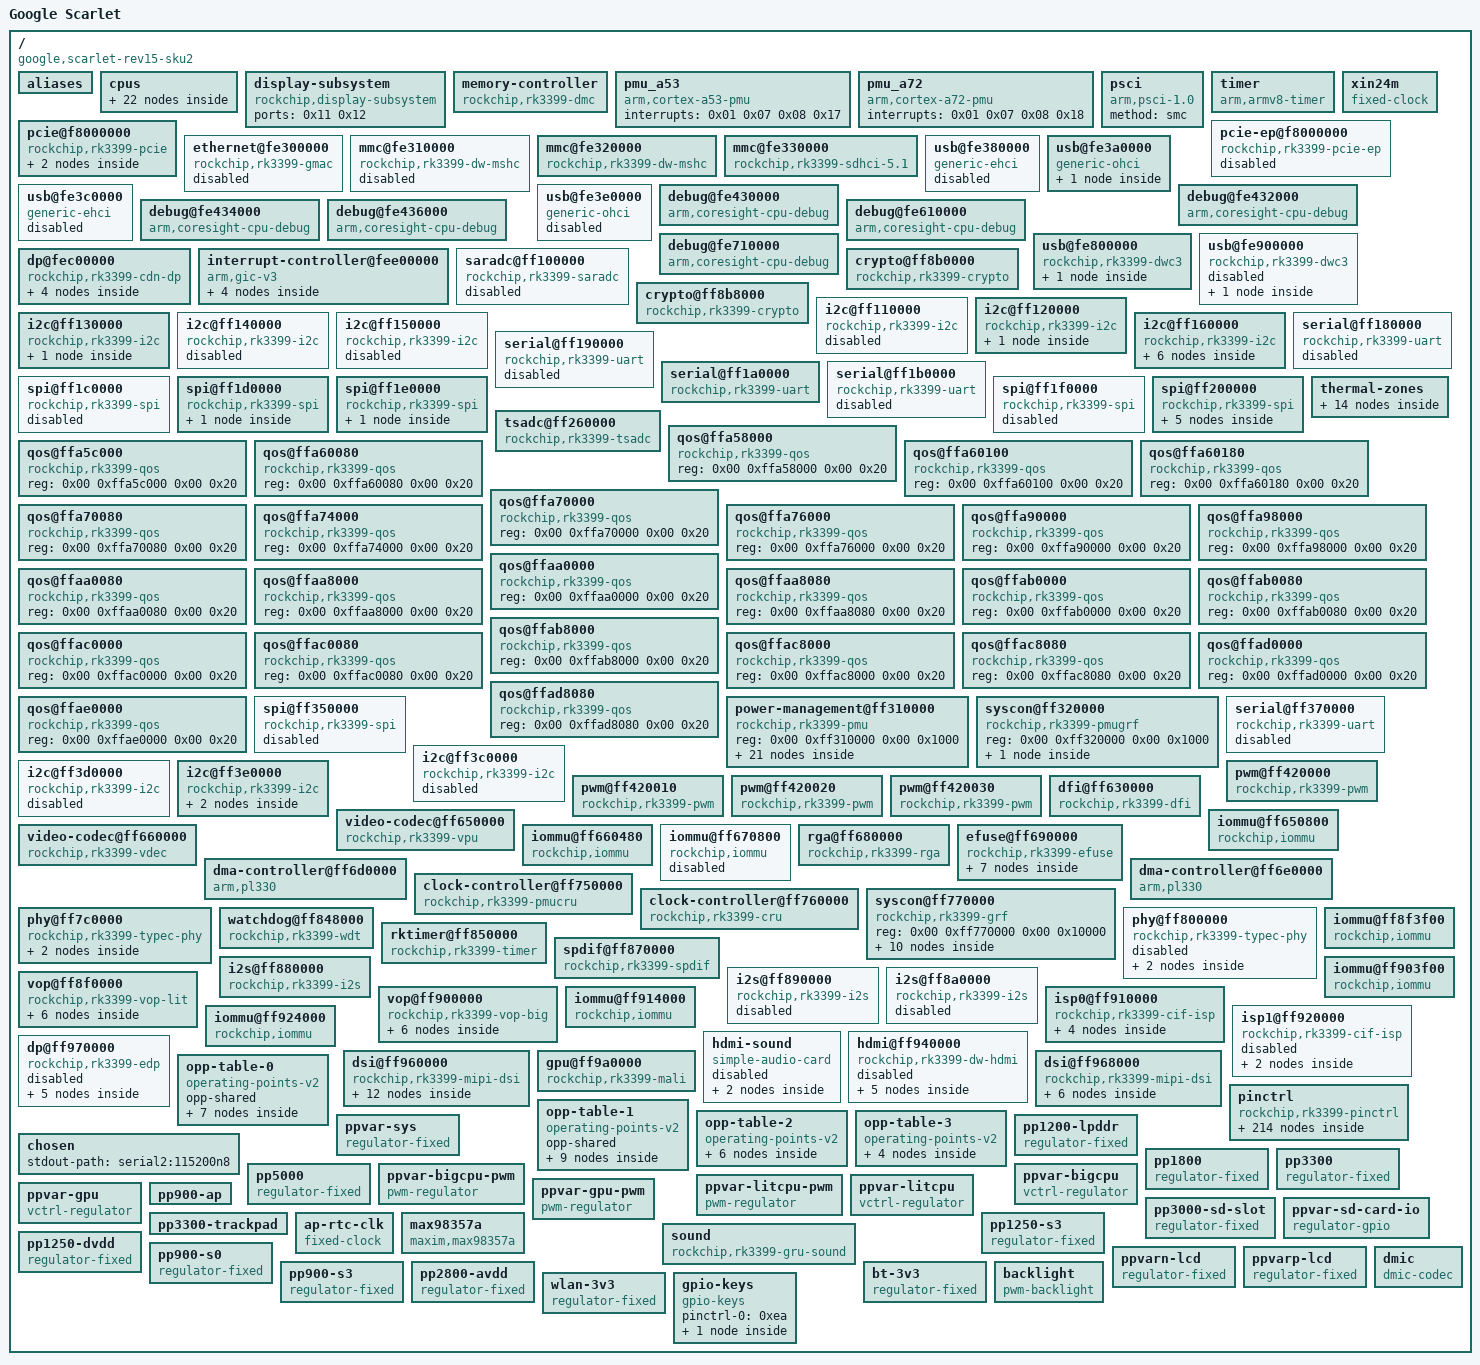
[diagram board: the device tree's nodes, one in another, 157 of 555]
/dts-v1/;

/ {
	compatible = "google,scarlet-rev15-sku2\0google,scarlet-rev15-sku4\0google,scarlet-rev15-sku6\0google,scarlet-rev15\0google,scarlet-rev14-sku2\0google,scarlet-rev14-sku4\0google,scarlet-rev14-sku6\0google,scarlet-rev14\0google,scarlet-rev13-sku2\0google,scarlet-rev13-sku4\0google,scarlet-rev13-sku6\0google,scarlet-rev13\0google,scarlet-rev12-sku2\0google,scarlet-rev12-sku4\0google,scarlet-rev12-sku6\0google,scarlet-rev12\0google,scarlet-rev11-sku2\0google,scarlet-rev11-sku4\0google,scarlet-rev11-sku6\0google,scarlet-rev11\0google,scarlet-rev10-sku2\0google,scarlet-rev10-sku4\0google,scarlet-rev10-sku6\0google,scarlet-rev10\0google,scarlet-rev9-sku2\0google,scarlet-rev9-sku4\0google,scarlet-rev9-sku6\0google,scarlet-rev9\0google,scarlet-rev8-sku2\0google,scarlet-rev8-sku4\0google,scarlet-rev8-sku6\0google,scarlet-rev8\0google,scarlet-rev7-sku2\0google,scarlet-rev7-sku4\0google,scarlet-rev7-sku6\0google,scarlet-rev7\0google,scarlet-rev6-sku2\0google,scarlet-rev6-sku4\0google,scarlet-rev6-sku6\0google,scarlet-rev6\0google,scarlet-rev5-sku2\0google,scarlet-rev5-sku4\0google,scarlet-rev5-sku6\0google,scarlet-rev5\0google,scarlet-rev4-sku2\0google,scarlet-rev4-sku4\0google,scarlet-rev4-sku6\0google,scarlet-rev4\0google,scarlet\0google,gru\0rockchip,rk3399";
	interrupt-parent = <0x01>;
	#address-cells = <0x02>;
	#size-cells = <0x02>;
	chassis-type = "tablet";
	model = "Google Scarlet";

	aliases {
		gpio0 = "/pinctrl/gpio@ff720000";
		gpio1 = "/pinctrl/gpio@ff730000";
		gpio2 = "/pinctrl/gpio@ff780000";
		gpio3 = "/pinctrl/gpio@ff788000";
		gpio4 = "/pinctrl/gpio@ff790000";
		i2c0 = "/i2c@ff3c0000";
		i2c1 = "/i2c@ff110000";
		i2c2 = "/i2c@ff120000";
		i2c3 = "/i2c@ff130000";
		i2c4 = "/i2c@ff3d0000";
		i2c5 = "/i2c@ff140000";
		i2c6 = "/i2c@ff150000";
		i2c7 = "/i2c@ff160000";
		i2c8 = "/i2c@ff3e0000";
		serial0 = "/serial@ff180000";
		serial1 = "/serial@ff190000";
		serial2 = "/serial@ff1a0000";
		serial3 = "/serial@ff1b0000";
		serial4 = "/serial@ff370000";
		spi0 = "/spi@ff1c0000";
		spi1 = "/spi@ff1d0000";
		spi2 = "/spi@ff1e0000";
		spi3 = "/spi@ff350000";
		spi4 = "/spi@ff1f0000";
		spi5 = "/spi@ff200000";
		mmc0 = "/mmc@fe320000";
		mmc1 = "/mmc@fe330000";
	};

	cpus {
		#address-cells = <0x02>;
		#size-cells = <0x00>;

		cpu-map {

			cluster0 {

				core0 {
					cpu = <0x02>;
				};

				core1 {
					cpu = <0x03>;
				};

				core2 {
					cpu = <0x04>;
				};

				core3 {
					cpu = <0x05>;
				};
			};

			cluster1 {

				core0 {
					cpu = <0x06>;
				};

				core1 {
					cpu = <0x07>;
				};
			};
		};

		cpu@0 {
			device_type = "cpu";
			compatible = "arm,cortex-a53";
			reg = <0x00 0x00>;
			enable-method = "psci";
			capacity-dmips-mhz = <0x1e5>;
			clocks = <0x08 0x08>;
			#cooling-cells = <0x02>;
			dynamic-power-coefficient = <0x64>;
			cpu-idle-states = <0x09 0x0a>;
			i-cache-size = <0x8000>;
			i-cache-line-size = <0x40>;
			i-cache-sets = <0x100>;
			d-cache-size = <0x8000>;
			d-cache-line-size = <0x40>;
			d-cache-sets = <0x80>;
			next-level-cache = <0x0b>;
			operating-points-v2 = <0x0c>;
			cpu-supply = <0x0d>;
			phandle = <0x02>;
		};

		cpu@1 {
			device_type = "cpu";
			compatible = "arm,cortex-a53";
			reg = <0x00 0x01>;
			enable-method = "psci";
			capacity-dmips-mhz = <0x1e5>;
			clocks = <0x08 0x08>;
			#cooling-cells = <0x02>;
			dynamic-power-coefficient = <0x64>;
			cpu-idle-states = <0x09 0x0a>;
			i-cache-size = <0x8000>;
			i-cache-line-size = <0x40>;
			i-cache-sets = <0x100>;
			d-cache-size = <0x8000>;
			d-cache-line-size = <0x40>;
			d-cache-sets = <0x80>;
			next-level-cache = <0x0b>;
			operating-points-v2 = <0x0c>;
			cpu-supply = <0x0d>;
			phandle = <0x03>;
		};

		cpu@2 {
			device_type = "cpu";
			compatible = "arm,cortex-a53";
			reg = <0x00 0x02>;
			enable-method = "psci";
			capacity-dmips-mhz = <0x1e5>;
			clocks = <0x08 0x08>;
			#cooling-cells = <0x02>;
			dynamic-power-coefficient = <0x64>;
			cpu-idle-states = <0x09 0x0a>;
			i-cache-size = <0x8000>;
			i-cache-line-size = <0x40>;
			i-cache-sets = <0x100>;
			d-cache-size = <0x8000>;
			d-cache-line-size = <0x40>;
			d-cache-sets = <0x80>;
			next-level-cache = <0x0b>;
			operating-points-v2 = <0x0c>;
			cpu-supply = <0x0d>;
			phandle = <0x04>;
		};

		cpu@3 {
			device_type = "cpu";
			compatible = "arm,cortex-a53";
			reg = <0x00 0x03>;
			enable-method = "psci";
			capacity-dmips-mhz = <0x1e5>;
			clocks = <0x08 0x08>;
			#cooling-cells = <0x02>;
			dynamic-power-coefficient = <0x64>;
			cpu-idle-states = <0x09 0x0a>;
			i-cache-size = <0x8000>;
			i-cache-line-size = <0x40>;
			i-cache-sets = <0x100>;
			d-cache-size = <0x8000>;
			d-cache-line-size = <0x40>;
			d-cache-sets = <0x80>;
			next-level-cache = <0x0b>;
			operating-points-v2 = <0x0c>;
			cpu-supply = <0x0d>;
			phandle = <0x05>;
		};

		cpu@100 {
			device_type = "cpu";
			compatible = "arm,cortex-a72";
			reg = <0x00 0x100>;
			enable-method = "psci";
			capacity-dmips-mhz = <0x400>;
			clocks = <0x08 0x09>;
			#cooling-cells = <0x02>;
			dynamic-power-coefficient = <0x1b4>;
			cpu-idle-states = <0x09 0x0a>;
			i-cache-size = <0xc000>;
			i-cache-line-size = <0x40>;
			i-cache-sets = <0x100>;
			d-cache-size = <0x8000>;
			d-cache-line-size = <0x40>;
			d-cache-sets = <0x100>;
			next-level-cache = <0x0e>;
			operating-points-v2 = <0x0f>;
			cpu-supply = <0x10>;
			phandle = <0x06>;

			thermal-idle {
				#cooling-cells = <0x02>;
				duration-us = <0x2710>;
				exit-latency-us = <0x1f4>;
			};
		};

		cpu@101 {
			device_type = "cpu";
			compatible = "arm,cortex-a72";
			reg = <0x00 0x101>;
			enable-method = "psci";
			capacity-dmips-mhz = <0x400>;
			clocks = <0x08 0x09>;
			#cooling-cells = <0x02>;
			dynamic-power-coefficient = <0x1b4>;
			cpu-idle-states = <0x09 0x0a>;
			i-cache-size = <0xc000>;
			i-cache-line-size = <0x40>;
			i-cache-sets = <0x100>;
			d-cache-size = <0x8000>;
			d-cache-line-size = <0x40>;
			d-cache-sets = <0x100>;
			next-level-cache = <0x0e>;
			operating-points-v2 = <0x0f>;
			cpu-supply = <0x10>;
			phandle = <0x07>;

			thermal-idle {
				#cooling-cells = <0x02>;
				duration-us = <0x2710>;
				exit-latency-us = <0x1f4>;
			};
		};

		l2-cache-cluster0 {
			compatible = "cache";
			cache-level = <0x02>;
			cache-unified;
			cache-size = <0x80000>;
			cache-line-size = <0x40>;
			cache-sets = <0x200>;
			phandle = <0x0b>;
		};

		l2-cache-cluster1 {
			compatible = "cache";
			cache-level = <0x02>;
			cache-unified;
			cache-size = <0x100000>;
			cache-line-size = <0x40>;
			cache-sets = <0x400>;
			phandle = <0x0e>;
		};

		idle-states {
			entry-method = "psci";

			cpu-sleep {
				compatible = "arm,idle-state";
				local-timer-stop;
				arm,psci-suspend-param = <0x10000>;
				entry-latency-us = <0x78>;
				exit-latency-us = <0xfa>;
				min-residency-us = <0x384>;
				phandle = <0x09>;
			};

			cluster-sleep {
				compatible = "arm,idle-state";
				local-timer-stop;
				arm,psci-suspend-param = <0x1010000>;
				entry-latency-us = <0x190>;
				exit-latency-us = <0x1f4>;
				min-residency-us = <0x7d0>;
				phandle = <0x0a>;
			};
		};
	};

	display-subsystem {
		compatible = "rockchip,display-subsystem";
		ports = <0x11 0x12>;
	};

	memory-controller {
		compatible = "rockchip,rk3399-dmc";
		rockchip,pmu = <0x13>;
		devfreq-events = <0x14>;
		clocks = <0x08 0xa8>;
		clock-names = "dmc_clk";
		status = "okay";
		operating-points-v2 = <0x15>;
		rockchip,pd-idle-ns = <0xa0>;
		rockchip,sr-idle-ns = <0x2800>;
		rockchip,sr-mc-gate-idle-ns = <0xa000>;
		rockchip,srpd-lite-idle-ns = <0xf000>;
		rockchip,standby-idle-ns = <0x14000>;
		rockchip,ddr3_odt_dis_freq = <0x27b25a80>;
		rockchip,lpddr3_odt_dis_freq = <0x27b25a80>;
		rockchip,lpddr4_odt_dis_freq = <0x27b25a80>;
		rockchip,sr-mc-gate-idle-dis-freq-hz = <0x3b9aca00>;
		rockchip,srpd-lite-idle-dis-freq-hz = <0x00>;
		rockchip,standby-idle-dis-freq-hz = "7P(";
		center-supply = <0x16>;
	};

	pmu_a53 {
		compatible = "arm,cortex-a53-pmu";
		interrupts = <0x01 0x07 0x08 0x17>;
	};

	pmu_a72 {
		compatible = "arm,cortex-a72-pmu";
		interrupts = <0x01 0x07 0x08 0x18>;
	};

	psci {
		compatible = "arm,psci-1.0";
		method = "smc";
	};

	timer {
		compatible = "arm,armv8-timer";
		interrupts = <0x01 0x0d 0x08 0x00 0x01 0x0e 0x08 0x00 0x01 0x0b 0x08 0x00 0x01 0x0a 0x08 0x00>;
		arm,no-tick-in-suspend;
	};

	xin24m {
		compatible = "fixed-clock";
		clock-frequency = <0x16e3600>;
		clock-output-names = "xin24m";
		#clock-cells = <0x00>;
		phandle = <0x96>;
	};

	pcie@f8000000 {
		compatible = "rockchip,rk3399-pcie";
		reg = <0x00 0xf8000000 0x00 0x2000000 0x00 0xfd000000 0x00 0x1000000>;
		reg-names = "axi-base\0apb-base";
		device_type = "pci";
		#address-cells = <0x03>;
		#size-cells = <0x02>;
		#interrupt-cells = <0x01>;
		aspm-no-l0s;
		bus-range = <0x00 0x1f>;
		clocks = <0x08 0xc5 0x08 0xc4 0x08 0x147 0x08 0xa0>;
		clock-names = "aclk\0aclk-perf\0hclk\0pm";
		interrupts = <0x00 0x31 0x04 0x00 0x00 0x32 0x04 0x00 0x00 0x33 0x04 0x00>;
		interrupt-names = "sys\0legacy\0client";
		interrupt-map-mask = <0x00 0x00 0x00 0x07>;
		interrupt-map = <0x00 0x00 0x00 0x01 0x19 0x00 0x00 0x00 0x00 0x02 0x19 0x01 0x00 0x00 0x00 0x03 0x19 0x02 0x00 0x00 0x00 0x04 0x19 0x03>;
		max-link-speed = <0x01>;
		msi-map = <0x00 0x1a 0x00 0x1000>;
		phys = <0x1b 0x00 0x1b 0x01 0x1b 0x02 0x1b 0x03>;
		phy-names = "pcie-phy-0\0pcie-phy-1\0pcie-phy-2\0pcie-phy-3";
		ranges = <0x82000000 0x00 0xfa000000 0x00 0xfa000000 0x00 0x1e00000 0x81000000 0x00 0xfbe00000 0x00 0xfbe00000 0x00 0x100000>;
		resets = <0x08 0x82 0x08 0x83 0x08 0x84 0x08 0x85 0x08 0x86 0x08 0x81 0x08 0x80>;
		reset-names = "core\0mgmt\0mgmt-sticky\0pipe\0pm\0pclk\0aclk";
		status = "okay";
		ep-gpios = <0x1c 0x03 0x00>;
		pinctrl-names = "default";
		pinctrl-0 = <0x1d 0x1e>;
		vpcie3v3-supply = <0x1f>;
		vpcie1v8-supply = <0x20>;
		vpcie0v9-supply = <0x16>;

		interrupt-controller {
			interrupt-controller;
			#address-cells = <0x00>;
			#interrupt-cells = <0x01>;
			phandle = <0x19>;
		};

		pcie@0,0 {
			reg = <0x00 0x00 0x00 0x00 0x00>;
			#address-cells = <0x03>;
			#size-cells = <0x02>;
			ranges;
			device_type = "pci";
		};
	};

	pcie-ep@f8000000 {
		compatible = "rockchip,rk3399-pcie-ep";
		reg = <0x00 0xfd000000 0x00 0x1000000 0x00 0xfa000000 0x00 0x2000000>;
		reg-names = "apb-base\0mem-base";
		clocks = <0x08 0xc5 0x08 0xc4 0x08 0x147 0x08 0xa0>;
		clock-names = "aclk\0aclk-perf\0hclk\0pm";
		max-functions = [08];
		num-lanes = <0x04>;
		resets = <0x08 0x82 0x08 0x83 0x08 0x84 0x08 0x85 0x08 0x86 0x08 0x81 0x08 0x80>;
		reset-names = "core\0mgmt\0mgmt-sticky\0pipe\0pm\0pclk\0aclk";
		phys = <0x1b 0x00 0x1b 0x01 0x1b 0x02 0x1b 0x03>;
		phy-names = "pcie-phy-0\0pcie-phy-1\0pcie-phy-2\0pcie-phy-3";
		rockchip,max-outbound-regions = <0x20>;
		pinctrl-names = "default";
		pinctrl-0 = <0x21>;
		status = "disabled";
	};

	ethernet@fe300000 {
		compatible = "rockchip,rk3399-gmac";
		reg = <0x00 0xfe300000 0x00 0x10000>;
		interrupts = <0x00 0x0c 0x04 0x00>;
		interrupt-names = "macirq";
		clocks = <0x08 0x69 0x08 0x67 0x08 0x68 0x08 0x66 0x08 0x6a 0x08 0xd5 0x08 0x166>;
		clock-names = "stmmaceth\0mac_clk_rx\0mac_clk_tx\0clk_mac_ref\0clk_mac_refout\0aclk_mac\0pclk_mac";
		power-domains = <0x22 0x16>;
		resets = <0x08 0x89>;
		reset-names = "stmmaceth";
		rockchip,grf = <0x23>;
		snps,txpbl = <0x04>;
		status = "disabled";
	};

	mmc@fe310000 {
		compatible = "rockchip,rk3399-dw-mshc\0rockchip,rk3288-dw-mshc";
		reg = <0x00 0xfe310000 0x00 0x4000>;
		interrupts = <0x00 0x40 0x04 0x00>;
		max-frequency = <0x8f0d180>;
		clocks = <0x08 0x1ee 0x08 0x4d 0x08 0x9c 0x08 0x9d>;
		clock-names = "biu\0ciu\0ciu-drive\0ciu-sample";
		fifo-depth = <0x100>;
		power-domains = <0x22 0x1c>;
		resets = <0x08 0x79>;
		reset-names = "reset";
		status = "disabled";
	};

	mmc@fe320000 {
		compatible = "rockchip,rk3399-dw-mshc\0rockchip,rk3288-dw-mshc";
		reg = <0x00 0xfe320000 0x00 0x4000>;
		interrupts = <0x00 0x41 0x04 0x00>;
		max-frequency = <0x8f0d180>;
		assigned-clocks = <0x08 0x1cd>;
		assigned-clock-rates = <0xbebc200>;
		clocks = <0x08 0x1ce 0x08 0x4c 0x08 0x9a 0x08 0x9b>;
		clock-names = "biu\0ciu\0ciu-drive\0ciu-sample";
		fifo-depth = <0x100>;
		power-domains = <0x22 0x1b>;
		resets = <0x08 0x7a>;
		reset-names = "reset";
		status = "okay";
		pinctrl-names = "default";
		pinctrl-0 = <0x24 0x25 0x26 0x27 0x28>;
		bus-width = <0x04>;
		cap-mmc-highspeed;
		cap-sd-highspeed;
		cd-gpios = <0x29 0x0b 0x01>;
		disable-wp;
		sd-uhs-sdr12;
		sd-uhs-sdr25;
		sd-uhs-sdr50;
		sd-uhs-sdr104;
		vmmc-supply = <0x2a>;
		vqmmc-supply = <0x2b>;
	};

	mmc@fe330000 {
		compatible = "rockchip,rk3399-sdhci-5.1\0arasan,sdhci-5.1";
		reg = <0x00 0xfe330000 0x00 0x10000>;
		interrupts = <0x00 0x0b 0x04 0x00>;
		arasan,soc-ctl-syscon = <0x23>;
		assigned-clocks = <0x08 0x4e>;
		assigned-clock-rates = <0x8f0d180>;
		clocks = <0x08 0x4e 0x08 0xf0>;
		clock-names = "clk_xin\0clk_ahb";
		clock-output-names = "emmc_cardclock";
		#clock-cells = <0x00>;
		phys = <0x2c>;
		phy-names = "phy_arasan";
		power-domains = <0x22 0x17>;
		disable-cqe-dcmd;
		status = "okay";
		bus-width = <0x08>;
		mmc-hs400-1_8v;
		mmc-hs400-enhanced-strobe;
		non-removable;
		phandle = <0x97>;
	};

	usb@fe380000 {
		compatible = "generic-ehci";
		reg = <0x00 0xfe380000 0x00 0x20000>;
		interrupts = <0x00 0x1a 0x04 0x00>;
		clocks = <0x08 0x1c8 0x08 0x1c9 0x2d>;
		phys = <0x2e>;
		phy-names = "usb";
		status = "disabled";
	};

	usb@fe3a0000 {
		compatible = "generic-ohci";
		reg = <0x00 0xfe3a0000 0x00 0x20000>;
		interrupts = <0x00 0x1c 0x04 0x00>;
		clocks = <0x08 0x1c8 0x08 0x1c9 0x2d>;
		phys = <0x2e>;
		phy-names = "usb";
		status = "okay";
		#address-cells = <0x01>;
		#size-cells = <0x00>;

		bluetooth@1 {
			compatible = "usbcf3,e300\0usb4ca,301a";
			reg = <0x01>;
			pinctrl-names = "default";
			pinctrl-0 = <0x2f>;
			interrupt-parent = <0x29>;
			interrupts = <0x02 0x04>;
			interrupt-names = "wakeup";
		};
	};

	usb@fe3c0000 {
		compatible = "generic-ehci";
		reg = <0x00 0xfe3c0000 0x00 0x20000>;
		interrupts = <0x00 0x1e 0x04 0x00>;
		clocks = <0x08 0x1ca 0x08 0x1cb 0x30>;
		phys = <0x31>;
		phy-names = "usb";
		status = "disabled";
	};

	usb@fe3e0000 {
		compatible = "generic-ohci";
		reg = <0x00 0xfe3e0000 0x00 0x20000>;
		interrupts = <0x00 0x20 0x04 0x00>;
		clocks = <0x08 0x1ca 0x08 0x1cb 0x30>;
		phys = <0x31>;
		phy-names = "usb";
		status = "disabled";
	};

	debug@fe430000 {
		compatible = "arm,coresight-cpu-debug\0arm,primecell";
		reg = <0x00 0xfe430000 0x00 0x1000>;
		clocks = <0x08 0x14d>;
		clock-names = "apb_pclk";
		cpu = <0x02>;
	};

	debug@fe432000 {
		compatible = "arm,coresight-cpu-debug\0arm,primecell";
		reg = <0x00 0xfe432000 0x00 0x1000>;
		clocks = <0x08 0x14d>;
		clock-names = "apb_pclk";
		cpu = <0x03>;
	};

	debug@fe434000 {
		compatible = "arm,coresight-cpu-debug\0arm,primecell";
		reg = <0x00 0xfe434000 0x00 0x1000>;
		clocks = <0x08 0x14d>;
		clock-names = "apb_pclk";
		cpu = <0x04>;
	};

	debug@fe436000 {
		compatible = "arm,coresight-cpu-debug\0arm,primecell";
		reg = <0x00 0xfe436000 0x00 0x1000>;
		clocks = <0x08 0x14d>;
		clock-names = "apb_pclk";
		cpu = <0x05>;
	};

	debug@fe610000 {
		compatible = "arm,coresight-cpu-debug\0arm,primecell";
		reg = <0x00 0xfe610000 0x00 0x1000>;
		clocks = <0x08 0x14c>;
		clock-names = "apb_pclk";
		cpu = <0x06>;
	};

	debug@fe710000 {
		compatible = "arm,coresight-cpu-debug\0arm,primecell";
		reg = <0x00 0xfe710000 0x00 0x1000>;
		clocks = <0x08 0x14c>;
		clock-names = "apb_pclk";
		cpu = <0x07>;
	};

	usb@fe800000 {
		compatible = "rockchip,rk3399-dwc3";
		#address-cells = <0x02>;
		#size-cells = <0x02>;
		ranges;
		clocks = <0x08 0x81 0x08 0x83 0x08 0xf6 0x08 0xf8 0x08 0xf4 0x08 0xf9>;
		clock-names = "ref_clk\0suspend_clk\0bus_clk\0aclk_usb3_rksoc_axi_perf\0aclk_usb3\0grf_clk";
		resets = <0x08 0x125>;
		reset-names = "usb3-otg";
		status = "okay";
		extcon = <0x32>;

		usb@fe800000 {
			compatible = "snps,dwc3";
			reg = <0x00 0xfe800000 0x00 0x100000>;
			interrupts = <0x00 0x69 0x04 0x00>;
			clocks = <0x08 0x81 0x08 0xf6 0x08 0x83>;
			clock-names = "ref\0bus_early\0suspend";
			dr_mode = "host";
			phys = <0x33 0x34>;
			phy-names = "usb2-phy\0usb3-phy";
			phy_type = "utmi_wide";
			snps,dis_enblslpm_quirk;
			snps,dis-u2-freeclk-exists-quirk;
			snps,dis_u2_susphy_quirk;
			snps,dis-del-phy-power-chg-quirk;
			snps,dis-tx-ipgap-linecheck-quirk;
			power-domains = <0x22 0x18>;
			status = "okay";
		};
	};

	usb@fe900000 {
		compatible = "rockchip,rk3399-dwc3";
		#address-cells = <0x02>;
		#size-cells = <0x02>;
		ranges;
		clocks = <0x08 0x82 0x08 0x84 0x08 0xf7 0x08 0xf8 0x08 0xf4 0x08 0xf9>;
		clock-names = "ref_clk\0suspend_clk\0bus_clk\0aclk_usb3_rksoc_axi_perf\0aclk_usb3\0grf_clk";
		resets = <0x08 0x126>;
		reset-names = "usb3-otg";
		status = "disabled";

		usb@fe900000 {
			compatible = "snps,dwc3";
			reg = <0x00 0xfe900000 0x00 0x100000>;
			interrupts = <0x00 0x6e 0x04 0x00>;
			clocks = <0x08 0x82 0x08 0xf7 0x08 0x84>;
			clock-names = "ref\0bus_early\0suspend";
			dr_mode = "otg";
			phys = <0x35 0x36>;
			phy-names = "usb2-phy\0usb3-phy";
			phy_type = "utmi_wide";
			snps,dis_enblslpm_quirk;
			snps,dis-u2-freeclk-exists-quirk;
			snps,dis_u2_susphy_quirk;
			snps,dis-del-phy-power-chg-quirk;
			snps,dis-tx-ipgap-linecheck-quirk;
			power-domains = <0x22 0x18>;
			status = "disabled";
		};
	};

	dp@fec00000 {
		compatible = "rockchip,rk3399-cdn-dp";
		reg = <0x00 0xfec00000 0x00 0x100000>;
		interrupts = <0x00 0x09 0x04 0x00>;
		assigned-clocks = <0x08 0x72 0x08 0xa1>;
		assigned-clock-rates = <0x5f5e100 0xbebc200>;
		clocks = <0x08 0x72 0x08 0x175 0x08 0xa1 0x08 0x16f>;
		clock-names = "core-clk\0pclk\0spdif\0grf";
		phys = <0x37>;
		power-domains = <0x22 0x15>;
		resets = <0x08 0x103 0x08 0x148 0x08 0x14a 0x08 0xfd>;
		reset-names = "spdif\0dptx\0apb\0core";
		rockchip,grf = <0x23>;
		#sound-dai-cells = <0x01>;
		status = "okay";
		extcon = <0x32>;
		phandle = <0xde>;

		ports {

			port {
				#address-cells = <0x01>;
				#size-cells = <0x00>;

				endpoint@0 {
					reg = <0x00>;
					remote-endpoint = <0x38>;
					phandle = <0xa6>;
				};

				endpoint@1 {
					reg = <0x01>;
					remote-endpoint = <0x39>;
					phandle = <0xa0>;
				};
			};
		};
	};

	interrupt-controller@fee00000 {
		compatible = "arm,gic-v3";
		#interrupt-cells = <0x04>;
		#address-cells = <0x02>;
		#size-cells = <0x02>;
		ranges;
		interrupt-controller;
		reg = <0x00 0xfee00000 0x00 0x10000 0x00 0xfef00000 0x00 0xc0000 0x00 0xfff00000 0x00 0x10000 0x00 0xfff10000 0x00 0x10000 0x00 0xfff20000 0x00 0x10000>;
		interrupts = <0x01 0x09 0x04 0x00>;
		phandle = <0x01>;

		msi-controller@fee20000 {
			compatible = "arm,gic-v3-its";
			msi-controller;
			#msi-cells = <0x01>;
			reg = <0x00 0xfee20000 0x00 0x20000>;
			phandle = <0x1a>;
		};

		ppi-partitions {

			interrupt-partition-0 {
				affinity = <0x02 0x03 0x04 0x05>;
				phandle = <0x17>;
			};

			interrupt-partition-1 {
				affinity = <0x06 0x07>;
				phandle = <0x18>;
			};
		};
	};

	saradc@ff100000 {
		compatible = "rockchip,rk3399-saradc";
		reg = <0x00 0xff100000 0x00 0x100>;
		interrupts = <0x00 0x3e 0x04 0x00>;
		#io-channel-cells = <0x01>;
		clocks = <0x08 0x50 0x08 0x165>;
		clock-names = "saradc\0apb_pclk";
		resets = <0x08 0xd4>;
		reset-names = "saradc-apb";
		status = "disabled";
	};

	crypto@ff8b0000 {
		compatible = "rockchip,rk3399-crypto";
		reg = <0x00 0xff8b0000 0x00 0x4000>;
		interrupts = <0x00 0x00 0x04 0x00>;
		clocks = <0x08 0x1d0 0x08 0x1d2 0x08 0x85>;
		clock-names = "hclk_master\0hclk_slave\0sclk";
		resets = <0x08 0xb5 0x08 0xae 0x08 0xaf>;
		reset-names = "master\0slave\0crypto-rst";
	};

	crypto@ff8b8000 {
		compatible = "rockchip,rk3399-crypto";
		reg = <0x00 0xff8b8000 0x00 0x4000>;
		interrupts = <0x00 0x87 0x04 0x00>;
		clocks = <0x08 0x1d1 0x08 0x1d3 0x08 0x86>;
		clock-names = "hclk_master\0hclk_slave\0sclk";
		resets = <0x08 0xba 0x08 0xb8 0x08 0xb9>;
		reset-names = "master\0slave\0crypto-rst";
	};

	i2c@ff110000 {
		compatible = "rockchip,rk3399-i2c";
		reg = <0x00 0xff110000 0x00 0x1000>;
		assigned-clocks = <0x08 0x41>;
		assigned-clock-rates = <0xbebc200>;
		clocks = <0x08 0x41 0x08 0x155>;
		clock-names = "i2c\0pclk";
		interrupts = <0x00 0x3b 0x04 0x00>;
		pinctrl-names = "default";
		pinctrl-0 = <0x3a>;
		#address-cells = <0x01>;
		#size-cells = <0x00>;
		status = "disabled";
	};

	i2c@ff120000 {
		compatible = "rockchip,rk3399-i2c";
		reg = <0x00 0xff120000 0x00 0x1000>;
		assigned-clocks = <0x08 0x42>;
		assigned-clock-rates = <0xbebc200>;
		clocks = <0x08 0x42 0x08 0x156>;
		clock-names = "i2c\0pclk";
		interrupts = <0x00 0x23 0x04 0x00>;
		pinctrl-names = "default";
		pinctrl-0 = <0x3b>;
		#address-cells = <0x01>;
		#size-cells = <0x00>;
		status = "okay";
		clock-frequency = <0x61a80>;
		i2c-scl-falling-time-ns = <0x32>;
		i2c-scl-rising-time-ns = <0x12c>;

		digitizer@9 {
			compatible = "hid-over-i2c";
			reg = <0x09>;
			interrupt-parent = <0x29>;
			interrupts = <0x00 0x08>;
			hid-descr-addr = <0x01>;
			pinctrl-names = "default";
			pinctrl-0 = <0x3c 0x3d>;
		};
	};

	i2c@ff130000 {
		compatible = "rockchip,rk3399-i2c";
		reg = <0x00 0xff130000 0x00 0x1000>;
		assigned-clocks = <0x08 0x43>;
		assigned-clock-rates = <0xbebc200>;
		clocks = <0x08 0x43 0x08 0x157>;
		clock-names = "i2c\0pclk";
		interrupts = <0x00 0x22 0x04 0x00>;
		pinctrl-names = "default";
		pinctrl-0 = <0x3e>;
		#address-cells = <0x01>;
		#size-cells = <0x00>;
		status = "okay";
		clock-frequency = <0x61a80>;
		i2c-scl-falling-time-ns = <0x32>;
		i2c-scl-rising-time-ns = <0x12c>;

		touchscreen@10 {
			compatible = "elan,ekth3500";
			reg = <0x10>;
			interrupt-parent = <0x29>;
			interrupts = <0x04 0x08>;
			pinctrl-names = "default";
			pinctrl-0 = <0x3f 0x40>;
			reset-gpios = <0x1c 0x0a 0x01>;
		};
	};

	i2c@ff140000 {
		compatible = "rockchip,rk3399-i2c";
		reg = <0x00 0xff140000 0x00 0x1000>;
		assigned-clocks = <0x08 0x44>;
		assigned-clock-rates = <0xbebc200>;
		clocks = <0x08 0x44 0x08 0x158>;
		clock-names = "i2c\0pclk";
		interrupts = <0x00 0x26 0x04 0x00>;
		pinctrl-names = "default";
		pinctrl-0 = <0x41>;
		#address-cells = <0x01>;
		#size-cells = <0x00>;
		status = "disabled";
	};

	i2c@ff150000 {
		compatible = "rockchip,rk3399-i2c";
		reg = <0x00 0xff150000 0x00 0x1000>;
		assigned-clocks = <0x08 0x45>;
		assigned-clock-rates = <0xbebc200>;
		clocks = <0x08 0x45 0x08 0x159>;
		clock-names = "i2c\0pclk";
		interrupts = <0x00 0x25 0x04 0x00>;
		pinctrl-names = "default";
		pinctrl-0 = <0x42>;
		#address-cells = <0x01>;
		#size-cells = <0x00>;
		status = "disabled";
	};

	i2c@ff160000 {
		compatible = "rockchip,rk3399-i2c";
		reg = <0x00 0xff160000 0x00 0x1000>;
		assigned-clocks = <0x08 0x46>;
		assigned-clock-rates = <0xbebc200>;
		clocks = <0x08 0x46 0x08 0x15a>;
		clock-names = "i2c\0pclk";
		interrupts = <0x00 0x24 0x04 0x00>;
		pinctrl-names = "default";
		pinctrl-0 = <0x43 0x44>;
		#address-cells = <0x01>;
		#size-cells = <0x00>;
		status = "okay";
		clock-frequency = <0x61a80>;
		i2c-scl-falling-time-ns = <0x32>;
		i2c-scl-rising-time-ns = <0x12c>;

		camera@36 {
			compatible = "ovti,ov5695";
			reg = <0x36>;
			pinctrl-names = "default";
			pinctrl-0 = <0x45>;
			clocks = <0x08 0xa9>;
			clock-names = "xvclk";
			avdd-supply = <0x46>;
			dvdd-supply = <0x47>;
			dovdd-supply = <0x20>;
			reset-gpios = <0x48 0x05 0x01>;

			port {

				endpoint {
					remote-endpoint = <0x49>;
					data-lanes = <0x01 0x02>;
					phandle = <0xa9>;
				};
			};
		};

		camera@3c {
			compatible = "ovti,ov2685";
			reg = <0x3c>;
			pinctrl-names = "default";
			pinctrl-0 = <0x4a>;
			clocks = <0x08 0xa9>;
			clock-names = "xvclk";
			avdd-supply = <0x46>;
			dovdd-supply = <0x20>;
			dvdd-supply = <0x20>;
			reset-gpios = <0x48 0x03 0x01>;

			port {

				endpoint {
					remote-endpoint = <0x4b>;
					data-lanes = <0x01>;
					phandle = <0xaa>;
				};
			};
		};
	};

	serial@ff180000 {
		compatible = "rockchip,rk3399-uart\0snps,dw-apb-uart";
		reg = <0x00 0xff180000 0x00 0x100>;
		clocks = <0x08 0x51 0x08 0x160>;
		clock-names = "baudclk\0apb_pclk";
		interrupts = <0x00 0x63 0x04 0x00>;
		reg-shift = <0x02>;
		reg-io-width = <0x04>;
		pinctrl-names = "default";
		pinctrl-0 = <0x4c>;
		status = "disabled";
	};

	serial@ff190000 {
		compatible = "rockchip,rk3399-uart\0snps,dw-apb-uart";
		reg = <0x00 0xff190000 0x00 0x100>;
		clocks = <0x08 0x52 0x08 0x161>;
		clock-names = "baudclk\0apb_pclk";
		interrupts = <0x00 0x62 0x04 0x00>;
		reg-shift = <0x02>;
		reg-io-width = <0x04>;
		pinctrl-names = "default";
		pinctrl-0 = <0x4d>;
		status = "disabled";
	};

	serial@ff1a0000 {
		compatible = "rockchip,rk3399-uart\0snps,dw-apb-uart";
		reg = <0x00 0xff1a0000 0x00 0x100>;
		clocks = <0x08 0x53 0x08 0x162>;
		clock-names = "baudclk\0apb_pclk";
		interrupts = <0x00 0x64 0x04 0x00>;
		reg-shift = <0x02>;
		reg-io-width = <0x04>;
		pinctrl-names = "default";
		pinctrl-0 = <0x4e>;
		status = "okay";
	};

	serial@ff1b0000 {
		compatible = "rockchip,rk3399-uart\0snps,dw-apb-uart";
		reg = <0x00 0xff1b0000 0x00 0x100>;
		clocks = <0x08 0x54 0x08 0x163>;
		clock-names = "baudclk\0apb_pclk";
		interrupts = <0x00 0x65 0x04 0x00>;
		reg-shift = <0x02>;
		reg-io-width = <0x04>;
		pinctrl-names = "default";
		pinctrl-0 = <0x4f>;
		status = "disabled";
	};

	spi@ff1c0000 {
		compatible = "rockchip,rk3399-spi\0rockchip,rk3066-spi";
		reg = <0x00 0xff1c0000 0x00 0x1000>;
		clocks = <0x08 0x47 0x08 0x15b>;
		clock-names = "spiclk\0apb_pclk";
		interrupts = <0x00 0x44 0x04 0x00>;
		dmas = <0x50 0x0a 0x50 0x0b>;
		dma-names = "tx\0rx";
		pinctrl-names = "default";
		pinctrl-0 = <0x51 0x52 0x53 0x54>;
		#address-cells = <0x01>;
		#size-cells = <0x00>;
		status = "disabled";
	};

	spi@ff1d0000 {
		compatible = "rockchip,rk3399-spi\0rockchip,rk3066-spi";
		reg = <0x00 0xff1d0000 0x00 0x1000>;
		clocks = <0x08 0x48 0x08 0x15c>;
		clock-names = "spiclk\0apb_pclk";
		interrupts = <0x00 0x35 0x04 0x00>;
		dmas = <0x50 0x0c 0x50 0x0d>;
		dma-names = "tx\0rx";
		pinctrl-names = "default\0sleep";
		pinctrl-0 = <0x55 0x56 0x57 0x58>;
		#address-cells = <0x01>;
		#size-cells = <0x00>;
		status = "okay";
		pinctrl-1 = <0x59>;

		flash@0 {
			compatible = "jedec,spi-nor";
			reg = <0x00>;
			spi-max-frequency = <0x989680>;
		};
	};

	spi@ff1e0000 {
		compatible = "rockchip,rk3399-spi\0rockchip,rk3066-spi";
		reg = <0x00 0xff1e0000 0x00 0x1000>;
		clocks = <0x08 0x49 0x08 0x15d>;
		clock-names = "spiclk\0apb_pclk";
		interrupts = <0x00 0x34 0x04 0x00>;
		dmas = <0x50 0x0e 0x50 0x0f>;
		dma-names = "tx\0rx";
		pinctrl-names = "default";
		pinctrl-0 = <0x5a 0x5b 0x5c 0x5d>;
		#address-cells = <0x01>;
		#size-cells = <0x00>;
		status = "okay";

		tpm@0 {
			compatible = "google,cr50";
			reg = <0x00>;
			interrupt-parent = <0x29>;
			interrupts = <0x11 0x01>;
			pinctrl-names = "default";
			pinctrl-0 = <0x5e>;
			spi-max-frequency = "\0\f5";
		};
	};

	spi@ff1f0000 {
		compatible = "rockchip,rk3399-spi\0rockchip,rk3066-spi";
		reg = <0x00 0xff1f0000 0x00 0x1000>;
		clocks = <0x08 0x4a 0x08 0x15e>;
		clock-names = "spiclk\0apb_pclk";
		interrupts = <0x00 0x43 0x04 0x00>;
		dmas = <0x50 0x12 0x50 0x13>;
		dma-names = "tx\0rx";
		pinctrl-names = "default";
		pinctrl-0 = <0x5f 0x60 0x61 0x62>;
		#address-cells = <0x01>;
		#size-cells = <0x00>;
		status = "disabled";
	};

	spi@ff200000 {
		compatible = "rockchip,rk3399-spi\0rockchip,rk3066-spi";
		reg = <0x00 0xff200000 0x00 0x1000>;
		clocks = <0x08 0x4b 0x08 0x15f>;
		clock-names = "spiclk\0apb_pclk";
		interrupts = <0x00 0x84 0x04 0x00>;
		dmas = <0x63 0x08 0x63 0x09>;
		dma-names = "tx\0rx";
		pinctrl-names = "default";
		pinctrl-0 = <0x64 0x65 0x66 0x67>;
		power-domains = <0x22 0x1c>;
		#address-cells = <0x01>;
		#size-cells = <0x00>;
		status = "okay";

		ec@0 {
			compatible = "google,cros-ec-spi";
			reg = <0x00>;
			interrupt-parent = <0x29>;
			interrupts = <0x12 0x08>;
			pinctrl-names = "default";
			pinctrl-0 = <0x68>;
			spi-max-frequency = <0x2dc6c0>;

			i2c-tunnel {
				compatible = "google,cros-ec-i2c-tunnel";
				google,remote-bus = <0x00>;
				#address-cells = <0x01>;
				#size-cells = <0x00>;

				sbs-battery@b {
					compatible = "sbs,sbs-battery";
					reg = <0x0b>;
					sbs,i2c-retry-count = <0x02>;
					sbs,poll-retry-count = <0x01>;
				};
			};

			extcon0 {
				compatible = "google,extcon-usbc-cros-ec";
				google,usb-port-id = <0x00>;
				phandle = <0x32>;
			};

			keyboard-controller {
				compatible = "google,cros-ec-keyb";
				keypad,num-rows = <0x08>;
				keypad,num-columns = <0x0d>;
				google,needs-ghost-filter;
				linux,keymap = <0x2003b 0x302003c 0x202003d 0x102003e 0x304003f 0x2040040 0x1040041 0x2090042 0x1090043 0x40044 0x1007d 0x30030 0x50059 0x60031 0x8000d 0xa0064 0x1010001 0x1030022 0x1060023 0x1080028 0x10b000e 0x10c005c 0x200001d 0x201000f 0x2030014 0x205001b 0x2060015 0x2070056 0x208001a 0x20a007c 0x300007d 0x3010029 0x3030006 0x3060007 0x308000c 0x309008e 0x30b002b 0x30c005e 0x4000061 0x401001e 0x4020020 0x4030021 0x404001f 0x4050025 0x4060024 0x4080027 0x4090026 0x40a002b 0x40b001c 0x501002c 0x502002e 0x503002f 0x504002d 0x5050033 0x5060032 0x507002a 0x5080035 0x5090034 0x50b0039 0x6010002 0x6020004 0x6030005 0x6040003 0x6050009 0x6060008 0x608000b 0x609000a 0x60a0038 0x60b006c 0x60c006a 0x7010010 0x7020012 0x7030013 0x7040011 0x7050017 0x7060016 0x7070036 0x7080019 0x7090018 0x70b0067 0x70c0069>;
			};
		};
	};

	thermal-zones {

		cpu-thermal {
			polling-delay-passive = <0x64>;
			polling-delay = <0x3e8>;
			thermal-sensors = <0x69 0x00>;

			trips {

				cpu_alert0 {
					temperature = <0x101d0>;
					hysteresis = <0x7d0>;
					type = "passive";
					phandle = <0x6a>;
				};

				cpu_alert1 {
					temperature = <0x11558>;
					hysteresis = <0x7d0>;
					type = "passive";
					phandle = <0x6b>;
				};

				cpu_crit {
					temperature = <0x17318>;
					hysteresis = <0x7d0>;
					type = "critical";
				};
			};

			cooling-maps {

				map0 {
					trip = <0x6a>;
					cooling-device = <0x06 0xffffffff 0xffffffff 0x07 0xffffffff 0xffffffff>;
				};

				map1 {
					trip = <0x6b>;
					cooling-device = <0x02 0xffffffff 0xffffffff 0x03 0xffffffff 0xffffffff 0x04 0xffffffff 0xffffffff 0x05 0xffffffff 0xffffffff 0x06 0xffffffff 0xffffffff 0x07 0xffffffff 0xffffffff>;
				};
			};
		};

		gpu-thermal {
			polling-delay-passive = <0x64>;
			polling-delay = <0x3e8>;
			thermal-sensors = <0x69 0x01>;

			trips {

				gpu_alert0 {
					temperature = <0x124f8>;
					hysteresis = <0x7d0>;
					type = "passive";
					phandle = <0x6c>;
				};

				gpu_crit {
					temperature = <0x17318>;
					hysteresis = <0x7d0>;
					type = "critical";
				};
			};

			cooling-maps {

				map0 {
					trip = <0x6c>;
					cooling-device = <0x6d 0xffffffff 0xffffffff>;
				};
			};
		};
	};

	tsadc@ff260000 {
		compatible = "rockchip,rk3399-tsadc";
		reg = <0x00 0xff260000 0x00 0x100>;
		interrupts = <0x00 0x61 0x04 0x00>;
		assigned-clocks = <0x08 0x4f>;
		assigned-clock-rates = <0xb71b0>;
		clocks = <0x08 0x4f 0x08 0x164>;
		clock-names = "tsadc\0apb_pclk";
		resets = <0x08 0xe8>;
		reset-names = "tsadc-apb";
		rockchip,grf = <0x23>;
		rockchip,hw-tshut-temp = <0x17318>;
		pinctrl-names = "init\0default\0sleep";
		pinctrl-0 = <0x6e>;
		pinctrl-1 = <0x6f>;
		pinctrl-2 = <0x6e>;
		#thermal-sensor-cells = <0x01>;
		status = "okay";
		rockchip,hw-tshut-mode = <0x01>;
		rockchip,hw-tshut-polarity = <0x01>;
		phandle = <0x69>;
	};

	qos@ffa58000 {
		compatible = "rockchip,rk3399-qos\0syscon";
		reg = <0x00 0xffa58000 0x00 0x20>;
		phandle = <0x77>;
	};

	qos@ffa5c000 {
		compatible = "rockchip,rk3399-qos\0syscon";
		reg = <0x00 0xffa5c000 0x00 0x20>;
		phandle = <0x78>;
	};

	qos@ffa60080 {
		compatible = "rockchip,rk3399-qos\0syscon";
		reg = <0x00 0xffa60080 0x00 0x20>;
	};

	qos@ffa60100 {
		compatible = "rockchip,rk3399-qos\0syscon";
		reg = <0x00 0xffa60100 0x00 0x20>;
	};

	qos@ffa60180 {
		compatible = "rockchip,rk3399-qos\0syscon";
		reg = <0x00 0xffa60180 0x00 0x20>;
	};

	qos@ffa70000 {
		compatible = "rockchip,rk3399-qos\0syscon";
		reg = <0x00 0xffa70000 0x00 0x20>;
		phandle = <0x7b>;
	};

	qos@ffa70080 {
		compatible = "rockchip,rk3399-qos\0syscon";
		reg = <0x00 0xffa70080 0x00 0x20>;
		phandle = <0x7c>;
	};

	qos@ffa74000 {
		compatible = "rockchip,rk3399-qos\0syscon";
		reg = <0x00 0xffa74000 0x00 0x20>;
		phandle = <0x79>;
	};

	qos@ffa76000 {
		compatible = "rockchip,rk3399-qos\0syscon";
		reg = <0x00 0xffa76000 0x00 0x20>;
		phandle = <0x7a>;
	};

	qos@ffa90000 {
		compatible = "rockchip,rk3399-qos\0syscon";
		reg = <0x00 0xffa90000 0x00 0x20>;
		phandle = <0x7d>;
	};

	qos@ffa98000 {
		compatible = "rockchip,rk3399-qos\0syscon";
		reg = <0x00 0xffa98000 0x00 0x20>;
		phandle = <0x70>;
	};

	qos@ffaa0000 {
		compatible = "rockchip,rk3399-qos\0syscon";
		reg = <0x00 0xffaa0000 0x00 0x20>;
		phandle = <0x7e>;
	};

	qos@ffaa0080 {
		compatible = "rockchip,rk3399-qos\0syscon";
		reg = <0x00 0xffaa0080 0x00 0x20>;
		phandle = <0x7f>;
	};

	qos@ffaa8000 {
		compatible = "rockchip,rk3399-qos\0syscon";
		reg = <0x00 0xffaa8000 0x00 0x20>;
		phandle = <0x80>;
	};

	qos@ffaa8080 {
		compatible = "rockchip,rk3399-qos\0syscon";
		reg = <0x00 0xffaa8080 0x00 0x20>;
		phandle = <0x81>;
	};

	qos@ffab0000 {
		compatible = "rockchip,rk3399-qos\0syscon";
		reg = <0x00 0xffab0000 0x00 0x20>;
		phandle = <0x71>;
	};

	qos@ffab0080 {
		compatible = "rockchip,rk3399-qos\0syscon";
		reg = <0x00 0xffab0080 0x00 0x20>;
		phandle = <0x72>;
	};

	qos@ffab8000 {
		compatible = "rockchip,rk3399-qos\0syscon";
		reg = <0x00 0xffab8000 0x00 0x20>;
		phandle = <0x73>;
	};

	qos@ffac0000 {
		compatible = "rockchip,rk3399-qos\0syscon";
		reg = <0x00 0xffac0000 0x00 0x20>;
		phandle = <0x74>;
	};

	qos@ffac0080 {
		compatible = "rockchip,rk3399-qos\0syscon";
		reg = <0x00 0xffac0080 0x00 0x20>;
		phandle = <0x75>;
	};

	qos@ffac8000 {
		compatible = "rockchip,rk3399-qos\0syscon";
		reg = <0x00 0xffac8000 0x00 0x20>;
		phandle = <0x82>;
	};

	qos@ffac8080 {
		compatible = "rockchip,rk3399-qos\0syscon";
		reg = <0x00 0xffac8080 0x00 0x20>;
		phandle = <0x83>;
	};

	qos@ffad0000 {
		compatible = "rockchip,rk3399-qos\0syscon";
		reg = <0x00 0xffad0000 0x00 0x20>;
		phandle = <0x84>;
	};

	qos@ffad8080 {
		compatible = "rockchip,rk3399-qos\0syscon";
		reg = <0x00 0xffad8080 0x00 0x20>;
	};

	qos@ffae0000 {
		compatible = "rockchip,rk3399-qos\0syscon";
		reg = <0x00 0xffae0000 0x00 0x20>;
		phandle = <0x76>;
	};

	power-management@ff310000 {
		compatible = "rockchip,rk3399-pmu\0syscon\0simple-mfd";
		reg = <0x00 0xff310000 0x00 0x1000>;

		power-controller {
			compatible = "rockchip,rk3399-power-controller";
			#power-domain-cells = <0x01>;
			#address-cells = <0x01>;
			#size-cells = <0x00>;
			phandle = <0x22>;

			power-domain@34 {
				reg = <0x22>;
				clocks = <0x08 0xe1 0x08 0x1dd>;
				pm_qos = <0x70>;
				#power-domain-cells = <0x00>;
			};

			power-domain@33 {
				reg = <0x21>;
				clocks = <0x08 0xdc 0x08 0x1e5>;
				pm_qos = <0x71 0x72>;
				#power-domain-cells = <0x00>;
			};

			power-domain@31 {
				reg = <0x1f>;
				clocks = <0x08 0xeb 0x08 0x1ea>;
				pm_qos = <0x73>;
				#power-domain-cells = <0x00>;
			};

			power-domain@32 {
				reg = <0x20>;
				clocks = <0x08 0xed 0x08 0x1ec 0x08 0x9f 0x08 0x9e>;
				pm_qos = <0x74 0x75>;
				#power-domain-cells = <0x00>;
			};

			power-domain@35 {
				reg = <0x23>;
				clocks = <0x08 0xd0>;
				pm_qos = <0x76>;
				#power-domain-cells = <0x00>;
			};

			power-domain@25 {
				reg = <0x19>;
				clocks = <0x08 0x16c>;
				#power-domain-cells = <0x00>;
			};

			power-domain@23 {
				reg = <0x17>;
				clocks = <0x08 0xf0>;
				pm_qos = <0x77>;
				#power-domain-cells = <0x00>;
			};

			power-domain@22 {
				reg = <0x16>;
				clocks = <0x08 0xd5 0x08 0x166>;
				pm_qos = <0x78>;
				#power-domain-cells = <0x00>;
			};

			power-domain@27 {
				reg = <0x1b>;
				clocks = <0x08 0x1ce 0x08 0x4c>;
				pm_qos = <0x79>;
				#power-domain-cells = <0x00>;
			};

			power-domain@28 {
				reg = <0x1c>;
				clocks = <0x08 0x1ee>;
				pm_qos = <0x7a>;
				#power-domain-cells = <0x00>;
			};

			power-domain@8 {
				reg = <0x08>;
				clocks = <0x08 0x7e 0x08 0x7d>;
				#power-domain-cells = <0x00>;
			};

			power-domain@9 {
				reg = <0x09>;
				clocks = <0x08 0x80 0x08 0x7f>;
				#power-domain-cells = <0x00>;
			};

			power-domain@24 {
				reg = <0x18>;
				clocks = <0x08 0xf4>;
				pm_qos = <0x7b 0x7c>;
				#power-domain-cells = <0x00>;
			};

			power-domain@15 {
				reg = <0x0f>;
				#power-domain-cells = <0x01>;
				#address-cells = <0x01>;
				#size-cells = <0x00>;

				power-domain@21 {
					reg = <0x15>;
					clocks = <0x08 0xde 0x08 0x1e7 0x08 0x172>;
					pm_qos = <0x7d>;
					#power-domain-cells = <0x00>;
				};

				power-domain@19 {
					reg = <0x13>;
					clocks = <0x08 0xe5 0x08 0x1df>;
					pm_qos = <0x7e 0x7f>;
					#power-domain-cells = <0x00>;
				};

				power-domain@20 {
					reg = <0x14>;
					clocks = <0x08 0xe6 0x08 0x1e0>;
					pm_qos = <0x80 0x81>;
					#power-domain-cells = <0x00>;
				};

				power-domain@16 {
					reg = <0x10>;
					#power-domain-cells = <0x01>;
					#address-cells = <0x01>;
					#size-cells = <0x00>;

					power-domain@17 {
						reg = <0x11>;
						clocks = <0x08 0xd9 0x08 0x1d9>;
						pm_qos = <0x82 0x83>;
						#power-domain-cells = <0x00>;
					};

					power-domain@18 {
						reg = <0x12>;
						clocks = <0x08 0xdb 0x08 0x1db>;
						pm_qos = <0x84>;
						#power-domain-cells = <0x00>;
					};
				};
			};
		};
	};

	syscon@ff320000 {
		compatible = "rockchip,rk3399-pmugrf\0syscon\0simple-mfd";
		reg = <0x00 0xff320000 0x00 0x1000>;
		phandle = <0x13>;

		io-domains {
			compatible = "rockchip,rk3399-pmu-io-voltage-domain";
			status = "okay";
			pmu1830-supply = <0x20>;
		};
	};

	spi@ff350000 {
		compatible = "rockchip,rk3399-spi\0rockchip,rk3066-spi";
		reg = <0x00 0xff350000 0x00 0x1000>;
		clocks = <0x85 0x03 0x85 0x1f>;
		clock-names = "spiclk\0apb_pclk";
		interrupts = <0x00 0x3c 0x04 0x00>;
		pinctrl-names = "default";
		pinctrl-0 = <0x86 0x87 0x88 0x89>;
		#address-cells = <0x01>;
		#size-cells = <0x00>;
		status = "disabled";
	};

	serial@ff370000 {
		compatible = "rockchip,rk3399-uart\0snps,dw-apb-uart";
		reg = <0x00 0xff370000 0x00 0x100>;
		clocks = <0x85 0x06 0x85 0x22>;
		clock-names = "baudclk\0apb_pclk";
		interrupts = <0x00 0x66 0x04 0x00>;
		reg-shift = <0x02>;
		reg-io-width = <0x04>;
		pinctrl-names = "default";
		pinctrl-0 = <0x8a>;
		status = "disabled";
	};

	i2c@ff3c0000 {
		compatible = "rockchip,rk3399-i2c";
		reg = <0x00 0xff3c0000 0x00 0x1000>;
		assigned-clocks = <0x85 0x09>;
		assigned-clock-rates = <0xbebc200>;
		clocks = <0x85 0x09 0x85 0x1b>;
		clock-names = "i2c\0pclk";
		interrupts = <0x00 0x39 0x04 0x00>;
		pinctrl-names = "default";
		pinctrl-0 = <0x8b>;
		#address-cells = <0x01>;
		#size-cells = <0x00>;
		status = "disabled";
	};

	i2c@ff3d0000 {
		compatible = "rockchip,rk3399-i2c";
		reg = <0x00 0xff3d0000 0x00 0x1000>;
		assigned-clocks = <0x85 0x0a>;
		assigned-clock-rates = <0xbebc200>;
		clocks = <0x85 0x0a 0x85 0x1c>;
		clock-names = "i2c\0pclk";
		interrupts = <0x00 0x38 0x04 0x00>;
		pinctrl-names = "default";
		pinctrl-0 = <0x8c>;
		#address-cells = <0x01>;
		#size-cells = <0x00>;
		status = "disabled";
	};

	i2c@ff3e0000 {
		compatible = "rockchip,rk3399-i2c";
		reg = <0x00 0xff3e0000 0x00 0x1000>;
		assigned-clocks = <0x85 0x0b>;
		assigned-clock-rates = <0xbebc200>;
		clocks = <0x85 0x0b 0x85 0x1d>;
		clock-names = "i2c\0pclk";
		interrupts = <0x00 0x3a 0x04 0x00>;
		pinctrl-names = "default";
		pinctrl-0 = <0x8d>;
		#address-cells = <0x01>;
		#size-cells = <0x00>;
		status = "okay";
		clock-frequency = <0x61a80>;
		i2c-scl-falling-time-ns = <0x32>;
		i2c-scl-rising-time-ns = <0x12c>;

		da7219@1a {
			compatible = "dlg,da7219";
			reg = <0x1a>;
			interrupt-parent = <0x29>;
			interrupts = <0x17 0x08>;
			clocks = <0x08 0x59>;
			clock-names = "mclk";
			dlg,micbias-lvl = <0xa28>;
			dlg,mic-amp-in-sel = "diff";
			pinctrl-names = "default";
			pinctrl-0 = <0x8e>;
			VDD-supply = <0x20>;
			VDDMIC-supply = <0x8f>;
			VDDIO-supply = <0x20>;
			phandle = <0xdd>;

			da7219_aad {
				dlg,adc-1bit-rpt = <0x01>;
				dlg,btn-avg = <0x04>;
				dlg,btn-cfg = <0x32>;
				dlg,mic-det-thr = <0x1f4>;
				dlg,jack-ins-deb = <0x14>;
				dlg,jack-det-rate = "32_64";
				dlg,jack-rem-deb = <0x01>;
				dlg,a-d-btn-thr = <0x0a>;
				dlg,d-b-btn-thr = <0x16>;
				dlg,b-c-btn-thr = <0x21>;
				dlg,c-mic-btn-thr = <0x3e>;
			};
		};
	};

	pwm@ff420000 {
		compatible = "rockchip,rk3399-pwm\0rockchip,rk3288-pwm";
		reg = <0x00 0xff420000 0x00 0x10>;
		#pwm-cells = <0x03>;
		pinctrl-names = "default";
		pinctrl-0 = <0x90>;
		clocks = <0x85 0x1e>;
		status = "okay";
		phandle = <0xd3>;
	};

	pwm@ff420010 {
		compatible = "rockchip,rk3399-pwm\0rockchip,rk3288-pwm";
		reg = <0x00 0xff420010 0x00 0x10>;
		#pwm-cells = <0x03>;
		pinctrl-names = "default";
		pinctrl-0 = <0x91>;
		clocks = <0x85 0x1e>;
		status = "okay";
		phandle = <0xe8>;
	};

	pwm@ff420020 {
		compatible = "rockchip,rk3399-pwm\0rockchip,rk3288-pwm";
		reg = <0x00 0xff420020 0x00 0x10>;
		#pwm-cells = <0x03>;
		pinctrl-names = "default";
		pinctrl-0 = <0x92>;
		clocks = <0x85 0x1e>;
		status = "okay";
		phandle = <0xd1>;
	};

	pwm@ff420030 {
		compatible = "rockchip,rk3399-pwm\0rockchip,rk3288-pwm";
		reg = <0x00 0xff420030 0x00 0x10>;
		#pwm-cells = <0x03>;
		pinctrl-names = "default";
		pinctrl-0 = <0x93>;
		clocks = <0x85 0x1e>;
		status = "okay";
		phandle = <0xcf>;
	};

	dfi@ff630000 {
		reg = <0x00 0xff630000 0x00 0x4000>;
		compatible = "rockchip,rk3399-dfi";
		rockchip,pmu = <0x13>;
		interrupts = <0x00 0x83 0x04 0x00>;
		clocks = <0x08 0x179>;
		clock-names = "pclk_ddr_mon";
		status = "okay";
		phandle = <0x14>;
	};

	video-codec@ff650000 {
		compatible = "rockchip,rk3399-vpu";
		reg = <0x00 0xff650000 0x00 0x800>;
		interrupts = <0x00 0x72 0x04 0x00 0x00 0x71 0x04 0x00>;
		interrupt-names = "vepu\0vdpu";
		clocks = <0x08 0xeb 0x08 0x1ea>;
		clock-names = "aclk\0hclk";
		iommus = <0x94>;
		power-domains = <0x22 0x1f>;
	};

	iommu@ff650800 {
		compatible = "rockchip,iommu";
		reg = <0x00 0xff650800 0x00 0x40>;
		interrupts = <0x00 0x73 0x04 0x00>;
		clocks = <0x08 0xeb 0x08 0x1ea>;
		clock-names = "aclk\0iface";
		#iommu-cells = <0x00>;
		power-domains = <0x22 0x1f>;
		phandle = <0x94>;
	};

	video-codec@ff660000 {
		compatible = "rockchip,rk3399-vdec";
		reg = <0x00 0xff660000 0x00 0x480>;
		interrupts = <0x00 0x74 0x04 0x00>;
		clocks = <0x08 0xed 0x08 0x1ec 0x08 0x9f 0x08 0x9e>;
		clock-names = "axi\0ahb\0cabac\0core";
		iommus = <0x95>;
		power-domains = <0x22 0x20>;
	};

	iommu@ff660480 {
		compatible = "rockchip,iommu";
		reg = <0x00 0xff660480 0x00 0x40 0x00 0xff6604c0 0x00 0x40>;
		interrupts = <0x00 0x75 0x04 0x00>;
		clocks = <0x08 0xed 0x08 0x1ec>;
		clock-names = "aclk\0iface";
		power-domains = <0x22 0x20>;
		#iommu-cells = <0x00>;
		phandle = <0x95>;
	};

	iommu@ff670800 {
		compatible = "rockchip,iommu";
		reg = <0x00 0xff670800 0x00 0x40>;
		interrupts = <0x00 0x2a 0x04 0x00>;
		clocks = <0x08 0xe1 0x08 0x1dd>;
		clock-names = "aclk\0iface";
		#iommu-cells = <0x00>;
		status = "disabled";
	};

	rga@ff680000 {
		compatible = "rockchip,rk3399-rga";
		reg = <0x00 0xff680000 0x00 0x10000>;
		interrupts = <0x00 0x37 0x04 0x00>;
		clocks = <0x08 0xdc 0x08 0x1e5 0x08 0x6d>;
		clock-names = "aclk\0hclk\0sclk";
		resets = <0x08 0x6a 0x08 0x67 0x08 0x69>;
		reset-names = "core\0axi\0ahb";
		power-domains = <0x22 0x21>;
	};

	efuse@ff690000 {
		compatible = "rockchip,rk3399-efuse";
		reg = <0x00 0xff690000 0x00 0x80>;
		#address-cells = <0x01>;
		#size-cells = <0x01>;
		clocks = <0x08 0x17d>;
		clock-names = "pclk_efuse";

		cpu-id@7 {
			reg = <0x07 0x10>;
		};

		cpu-leakage@17 {
			reg = <0x17 0x01>;
		};

		gpu-leakage@18 {
			reg = <0x18 0x01>;
		};

		center-leakage@19 {
			reg = <0x19 0x01>;
		};

		cpu-leakage@1a {
			reg = <0x1a 0x01>;
		};

		logic-leakage@1b {
			reg = <0x1b 0x01>;
		};

		wafer-info@1c {
			reg = <0x1c 0x01>;
		};
	};

	dma-controller@ff6d0000 {
		compatible = "arm,pl330\0arm,primecell";
		reg = <0x00 0xff6d0000 0x00 0x4000>;
		interrupts = <0x00 0x05 0x04 0x00 0x00 0x06 0x04 0x00>;
		#dma-cells = <0x01>;
		arm,pl330-periph-burst;
		clocks = <0x08 0xd3>;
		clock-names = "apb_pclk";
		phandle = <0x63>;
	};

	dma-controller@ff6e0000 {
		compatible = "arm,pl330\0arm,primecell";
		reg = <0x00 0xff6e0000 0x00 0x4000>;
		interrupts = <0x00 0x07 0x04 0x00 0x00 0x08 0x04 0x00>;
		#dma-cells = <0x01>;
		arm,pl330-periph-burst;
		clocks = <0x08 0xd4>;
		clock-names = "apb_pclk";
		phandle = <0x50>;
	};

	clock-controller@ff750000 {
		compatible = "rockchip,rk3399-pmucru";
		reg = <0x00 0xff750000 0x00 0x1000>;
		clocks = <0x96>;
		clock-names = "xin24m";
		rockchip,grf = <0x13>;
		#clock-cells = <0x01>;
		#reset-cells = <0x01>;
		assigned-clocks = <0x85 0x01>;
		assigned-clock-rates = <0x284af100>;
		phandle = <0x85>;
	};

	clock-controller@ff760000 {
		compatible = "rockchip,rk3399-cru";
		reg = <0x00 0xff760000 0x00 0x1000>;
		clocks = <0x96>;
		clock-names = "xin24m";
		rockchip,grf = <0x23>;
		#clock-cells = <0x01>;
		#reset-cells = <0x01>;
		assigned-clocks = <0x08 0x05 0x08 0x04 0x08 0x06 0x08 0xc0 0x08 0x1c0 0x08 0x140 0x08 0xc2 0x08 0x1c1 0x08 0x142 0x08 0xc9 0x08 0x1c2 0x08 0x143 0x08 0xe3 0x08 0x106 0x08 0x178 0x08 0xde 0x08 0xed>;
		assigned-clock-rates = <0x23c34600 0x5f5e1000 0x3b9aca00 0x8f0d180 0x47868c0 0x23c3460 0x5f5e100 0x5f5e100 0x2faf080 0x2faf0800 0x5f5e100 0x2faf080 0x17d78400 0xbebc200 0xbebc200 0x17d78400 0x17d78400>;
		phandle = <0x08>;
	};

	syscon@ff770000 {
		compatible = "rockchip,rk3399-grf\0syscon\0simple-mfd";
		reg = <0x00 0xff770000 0x00 0x10000>;
		#address-cells = <0x01>;
		#size-cells = <0x01>;
		phandle = <0x23>;

		io-domains {
			compatible = "rockchip,rk3399-io-voltage-domain";
			status = "okay";
			audio-supply = <0x20>;
			bt656-supply = <0x20>;
			gpio1830-supply = <0x20>;
			sdmmc-supply = <0x2b>;
		};

		mipi-dphy-rx0 {
			compatible = "rockchip,rk3399-mipi-dphy-rx0";
			clocks = <0x08 0x77 0x08 0xa5 0x08 0x16f>;
			clock-names = "dphy-ref\0dphy-cfg\0grf";
			power-domains = <0x22 0x0f>;
			#phy-cells = <0x00>;
			status = "okay";
			phandle = <0xa8>;
		};

		usb2phy@e450 {
			compatible = "rockchip,rk3399-usb2phy";
			reg = <0xe450 0x10>;
			clocks = <0x08 0x7b>;
			clock-names = "phyclk";
			#clock-cells = <0x00>;
			clock-output-names = "clk_usbphy0_480m";
			status = "okay";
			phandle = <0x2d>;

			host-port {
				#phy-cells = <0x00>;
				interrupts = <0x00 0x1b 0x04 0x00>;
				interrupt-names = "linestate";
				status = "okay";
				phandle = <0x2e>;
			};

			otg-port {
				#phy-cells = <0x00>;
				interrupts = <0x00 0x67 0x04 0x00 0x00 0x68 0x04 0x00 0x00 0x6a 0x04 0x00>;
				interrupt-names = "otg-bvalid\0otg-id\0linestate";
				status = "okay";
				phandle = <0x33>;
			};
		};

		usb2phy@e460 {
			compatible = "rockchip,rk3399-usb2phy";
			reg = <0xe460 0x10>;
			clocks = <0x08 0x7c>;
			clock-names = "phyclk";
			#clock-cells = <0x00>;
			clock-output-names = "clk_usbphy1_480m";
			status = "disabled";
			phandle = <0x30>;

			host-port {
				#phy-cells = <0x00>;
				interrupts = <0x00 0x1f 0x04 0x00>;
				interrupt-names = "linestate";
				status = "okay";
				phandle = <0x31>;
			};

			otg-port {
				#phy-cells = <0x00>;
				interrupts = <0x00 0x6c 0x04 0x00 0x00 0x6d 0x04 0x00 0x00 0x6f 0x04 0x00>;
				interrupt-names = "otg-bvalid\0otg-id\0linestate";
				status = "okay";
				phandle = <0x35>;
			};
		};

		phy@f780 {
			compatible = "rockchip,rk3399-emmc-phy";
			reg = <0xf780 0x24>;
			clocks = <0x97>;
			clock-names = "emmcclk";
			drive-impedance-ohm = <0x32>;
			#phy-cells = <0x00>;
			status = "okay";
			phandle = <0x2c>;
		};

		pcie-phy {
			compatible = "rockchip,rk3399-pcie-phy";
			clocks = <0x08 0x8a>;
			clock-names = "refclk";
			#phy-cells = <0x01>;
			resets = <0x08 0x87>;
			reset-names = "phy";
			status = "okay";
			phandle = <0x1b>;
		};
	};

	phy@ff7c0000 {
		compatible = "rockchip,rk3399-typec-phy";
		reg = <0x00 0xff7c0000 0x00 0x40000>;
		clocks = <0x08 0x7e 0x08 0x7d>;
		clock-names = "tcpdcore\0tcpdphy-ref";
		assigned-clocks = <0x08 0x7e>;
		assigned-clock-rates = <0x2faf080>;
		power-domains = <0x22 0x08>;
		resets = <0x08 0x95 0x08 0x94 0x08 0x14c>;
		reset-names = "uphy\0uphy-pipe\0uphy-tcphy";
		rockchip,grf = <0x23>;
		status = "okay";
		extcon = <0x32>;

		dp-port {
			#phy-cells = <0x00>;
			phandle = <0x37>;
		};

		usb3-port {
			#phy-cells = <0x00>;
			phandle = <0x34>;
		};
	};

	phy@ff800000 {
		compatible = "rockchip,rk3399-typec-phy";
		reg = <0x00 0xff800000 0x00 0x40000>;
		clocks = <0x08 0x80 0x08 0x7f>;
		clock-names = "tcpdcore\0tcpdphy-ref";
		assigned-clocks = <0x08 0x80>;
		assigned-clock-rates = <0x2faf080>;
		power-domains = <0x22 0x09>;
		resets = <0x08 0x9d 0x08 0x9c 0x08 0x14d>;
		reset-names = "uphy\0uphy-pipe\0uphy-tcphy";
		rockchip,grf = <0x23>;
		status = "disabled";

		dp-port {
			#phy-cells = <0x00>;
		};

		usb3-port {
			#phy-cells = <0x00>;
			phandle = <0x36>;
		};
	};

	watchdog@ff848000 {
		compatible = "rockchip,rk3399-wdt\0snps,dw-wdt";
		reg = <0x00 0xff848000 0x00 0x100>;
		clocks = <0x08 0x17c>;
		interrupts = <0x00 0x78 0x04 0x00>;
	};

	rktimer@ff850000 {
		compatible = "rockchip,rk3399-timer";
		reg = <0x00 0xff850000 0x00 0x1000>;
		interrupts = <0x00 0x51 0x04 0x00>;
		clocks = <0x08 0x168 0x08 0x5a>;
		clock-names = "pclk\0timer";
	};

	spdif@ff870000 {
		compatible = "rockchip,rk3399-spdif";
		reg = <0x00 0xff870000 0x00 0x1000>;
		interrupts = <0x00 0x42 0x04 0x00>;
		dmas = <0x63 0x07>;
		dma-names = "tx";
		clock-names = "mclk\0hclk";
		clocks = <0x08 0x55 0x08 0x1d7>;
		power-domains = <0x22 0x1c>;
		#sound-dai-cells = <0x00>;
		status = "okay";
		phandle = <0xda>;
	};

	i2s@ff880000 {
		compatible = "rockchip,rk3399-i2s\0rockchip,rk3066-i2s";
		reg = <0x00 0xff880000 0x00 0x1000>;
		rockchip,grf = <0x23>;
		interrupts = <0x00 0x27 0x04 0x00>;
		dmas = <0x63 0x00 0x63 0x01>;
		dma-names = "tx\0rx";
		clock-names = "i2s_clk\0i2s_hclk";
		clocks = <0x08 0x56 0x08 0x1d4>;
		pinctrl-names = "bclk_on\0bclk_off";
		pinctrl-0 = <0x98>;
		pinctrl-1 = <0x99>;
		power-domains = <0x22 0x1c>;
		#sound-dai-cells = <0x00>;
		status = "okay";
		phandle = <0xd9>;
	};

	i2s@ff890000 {
		compatible = "rockchip,rk3399-i2s\0rockchip,rk3066-i2s";
		reg = <0x00 0xff890000 0x00 0x1000>;
		interrupts = <0x00 0x28 0x04 0x00>;
		dmas = <0x63 0x02 0x63 0x03>;
		dma-names = "tx\0rx";
		clock-names = "i2s_clk\0i2s_hclk";
		clocks = <0x08 0x57 0x08 0x1d5>;
		pinctrl-names = "default";
		pinctrl-0 = <0x9a>;
		power-domains = <0x22 0x1c>;
		#sound-dai-cells = <0x00>;
		status = "disabled";
	};

	i2s@ff8a0000 {
		compatible = "rockchip,rk3399-i2s\0rockchip,rk3066-i2s";
		reg = <0x00 0xff8a0000 0x00 0x1000>;
		interrupts = <0x00 0x29 0x04 0x00>;
		dmas = <0x63 0x04 0x63 0x05>;
		dma-names = "tx\0rx";
		clock-names = "i2s_clk\0i2s_hclk";
		clocks = <0x08 0x58 0x08 0x1d6>;
		power-domains = <0x22 0x1c>;
		#sound-dai-cells = <0x00>;
		status = "disabled";
		phandle = <0xad>;
	};

	vop@ff8f0000 {
		compatible = "rockchip,rk3399-vop-lit";
		reg = <0x00 0xff8f0000 0x00 0x2000 0x00 0xff8f2000 0x00 0x400>;
		interrupts = <0x00 0x77 0x04 0x00>;
		assigned-clocks = <0x08 0xdb 0x08 0x1db>;
		assigned-clock-rates = <0x17d78400 0x5f5e100>;
		clocks = <0x08 0xdb 0x08 0xb5 0x08 0x1db>;
		clock-names = "aclk_vop\0dclk_vop\0hclk_vop";
		iommus = <0x9b>;
		power-domains = <0x22 0x12>;
		resets = <0x08 0x113 0x08 0x117 0x08 0x119>;
		reset-names = "axi\0ahb\0dclk";
		status = "okay";

		port {
			#address-cells = <0x01>;
			#size-cells = <0x00>;
			phandle = <0x11>;

			endpoint@0 {
				reg = <0x00>;
				remote-endpoint = <0x9c>;
				phandle = <0xb2>;
			};

			endpoint@1 {
				reg = <0x01>;
				remote-endpoint = <0x9d>;
				phandle = <0xc0>;
			};

			endpoint@2 {
				reg = <0x02>;
				remote-endpoint = <0x9e>;
				phandle = <0xb0>;
			};

			endpoint@3 {
				reg = <0x03>;
				remote-endpoint = <0x9f>;
				phandle = <0xbc>;
			};

			endpoint@4 {
				reg = <0x04>;
				remote-endpoint = <0xa0>;
				phandle = <0x39>;
			};
		};
	};

	iommu@ff8f3f00 {
		compatible = "rockchip,iommu";
		reg = <0x00 0xff8f3f00 0x00 0x100>;
		interrupts = <0x00 0x77 0x04 0x00>;
		clocks = <0x08 0xdb 0x08 0x1db>;
		clock-names = "aclk\0iface";
		power-domains = <0x22 0x12>;
		#iommu-cells = <0x00>;
		status = "okay";
		phandle = <0x9b>;
	};

	vop@ff900000 {
		compatible = "rockchip,rk3399-vop-big";
		reg = <0x00 0xff900000 0x00 0x2000 0x00 0xff902000 0x00 0x1000>;
		interrupts = <0x00 0x76 0x04 0x00>;
		assigned-clocks = <0x08 0xd9 0x08 0x1d9>;
		assigned-clock-rates = <0x17d78400 0x5f5e100>;
		clocks = <0x08 0xd9 0x08 0xb4 0x08 0x1d9>;
		clock-names = "aclk_vop\0dclk_vop\0hclk_vop";
		iommus = <0xa1>;
		power-domains = <0x22 0x11>;
		resets = <0x08 0x112 0x08 0x116 0x08 0x118>;
		reset-names = "axi\0ahb\0dclk";
		status = "okay";

		port {
			#address-cells = <0x01>;
			#size-cells = <0x00>;
			phandle = <0x12>;

			endpoint@0 {
				reg = <0x00>;
				remote-endpoint = <0xa2>;
				phandle = <0xbf>;
			};

			endpoint@1 {
				reg = <0x01>;
				remote-endpoint = <0xa3>;
				phandle = <0xb1>;
			};

			endpoint@2 {
				reg = <0x02>;
				remote-endpoint = <0xa4>;
				phandle = <0xaf>;
			};

			endpoint@3 {
				reg = <0x03>;
				remote-endpoint = <0xa5>;
				phandle = <0xbb>;
			};

			endpoint@4 {
				reg = <0x04>;
				remote-endpoint = <0xa6>;
				phandle = <0x38>;
			};
		};
	};

	iommu@ff903f00 {
		compatible = "rockchip,iommu";
		reg = <0x00 0xff903f00 0x00 0x100>;
		interrupts = <0x00 0x76 0x04 0x00>;
		clocks = <0x08 0xd9 0x08 0x1d9>;
		clock-names = "aclk\0iface";
		power-domains = <0x22 0x11>;
		#iommu-cells = <0x00>;
		status = "okay";
		phandle = <0xa1>;
	};

	isp0@ff910000 {
		compatible = "rockchip,rk3399-cif-isp";
		reg = <0x00 0xff910000 0x00 0x4000>;
		interrupts = <0x00 0x2b 0x04 0x00>;
		clocks = <0x08 0x6e 0x08 0xe9 0x08 0x1e3>;
		clock-names = "isp\0aclk\0hclk";
		iommus = <0xa7>;
		phys = <0xa8>;
		phy-names = "dphy";
		power-domains = <0x22 0x13>;
		status = "okay";

		ports {
			#address-cells = <0x01>;
			#size-cells = <0x00>;

			port@0 {
				reg = <0x00>;
				#address-cells = <0x01>;
				#size-cells = <0x00>;

				endpoint@0 {
					reg = <0x00>;
					remote-endpoint = <0xa9>;
					data-lanes = <0x01 0x02>;
					phandle = <0x49>;
				};

				endpoint@1 {
					reg = <0x01>;
					remote-endpoint = <0xaa>;
					data-lanes = <0x01>;
					phandle = <0x4b>;
				};
			};
		};
	};

	iommu@ff914000 {
		compatible = "rockchip,iommu";
		reg = <0x00 0xff914000 0x00 0x100 0x00 0xff915000 0x00 0x100>;
		interrupts = <0x00 0x2b 0x04 0x00>;
		clocks = <0x08 0xe9 0x08 0x1e3>;
		clock-names = "aclk\0iface";
		#iommu-cells = <0x00>;
		power-domains = <0x22 0x13>;
		rockchip,disable-mmu-reset;
		status = "okay";
		phandle = <0xa7>;
	};

	isp1@ff920000 {
		compatible = "rockchip,rk3399-cif-isp";
		reg = <0x00 0xff920000 0x00 0x4000>;
		interrupts = <0x00 0x2c 0x04 0x00>;
		clocks = <0x08 0x6f 0x08 0xea 0x08 0x1e4>;
		clock-names = "isp\0aclk\0hclk";
		iommus = <0xab>;
		phys = <0xac>;
		phy-names = "dphy";
		power-domains = <0x22 0x14>;
		status = "disabled";

		ports {
			#address-cells = <0x01>;
			#size-cells = <0x00>;

			port@0 {
				reg = <0x00>;
				#address-cells = <0x01>;
				#size-cells = <0x00>;
			};
		};
	};

	iommu@ff924000 {
		compatible = "rockchip,iommu";
		reg = <0x00 0xff924000 0x00 0x100 0x00 0xff925000 0x00 0x100>;
		interrupts = <0x00 0x2c 0x04 0x00>;
		clocks = <0x08 0xea 0x08 0x1e4>;
		clock-names = "aclk\0iface";
		#iommu-cells = <0x00>;
		power-domains = <0x22 0x14>;
		rockchip,disable-mmu-reset;
		phandle = <0xab>;
	};

	hdmi-sound {
		compatible = "simple-audio-card";
		simple-audio-card,format = "i2s";
		simple-audio-card,mclk-fs = <0x100>;
		simple-audio-card,name = "hdmi-sound";
		status = "disabled";

		simple-audio-card,cpu {
			sound-dai = <0xad>;
		};

		simple-audio-card,codec {
			sound-dai = <0xae>;
		};
	};

	hdmi@ff940000 {
		compatible = "rockchip,rk3399-dw-hdmi";
		reg = <0x00 0xff940000 0x00 0x20000>;
		reg-io-width = <0x04>;
		interrupts = <0x00 0x17 0x04 0x00>;
		clocks = <0x08 0x174 0x08 0x71 0x08 0x70 0x08 0x16f 0x08 0x07>;
		clock-names = "iahb\0isfr\0cec\0grf\0ref";
		power-domains = <0x22 0x15>;
		rockchip,grf = <0x23>;
		#sound-dai-cells = <0x00>;
		status = "disabled";
		phandle = <0xae>;

		ports {
			#address-cells = <0x01>;
			#size-cells = <0x00>;

			port@0 {
				reg = <0x00>;
				#address-cells = <0x01>;
				#size-cells = <0x00>;

				endpoint@0 {
					reg = <0x00>;
					remote-endpoint = <0xaf>;
					phandle = <0xa4>;
				};

				endpoint@1 {
					reg = <0x01>;
					remote-endpoint = <0xb0>;
					phandle = <0x9e>;
				};
			};

			port@1 {
				reg = <0x01>;
			};
		};
	};

	dsi@ff960000 {
		compatible = "rockchip,rk3399-mipi-dsi\0snps,dw-mipi-dsi";
		reg = <0x00 0xff960000 0x00 0x8000>;
		interrupts = <0x00 0x2d 0x04 0x00>;
		clocks = <0x08 0xa2 0x08 0x170 0x08 0xa3 0x08 0x16f>;
		clock-names = "ref\0pclk\0phy_cfg\0grf";
		power-domains = <0x22 0x0f>;
		resets = <0x08 0xfb>;
		reset-names = "apb";
		rockchip,grf = <0x23>;
		#address-cells = <0x01>;
		#size-cells = <0x00>;
		status = "okay";
		clock-master;

		ports {
			#address-cells = <0x01>;
			#size-cells = <0x00>;

			port@0 {
				reg = <0x00>;
				#address-cells = <0x01>;
				#size-cells = <0x00>;

				endpoint@0 {
					reg = <0x00>;
					remote-endpoint = <0xb1>;
					phandle = <0xa3>;
				};

				endpoint@1 {
					reg = <0x01>;
					remote-endpoint = <0xb2>;
					phandle = <0x9c>;
				};
			};

			port@1 {
				reg = <0x01>;

				endpoint {
					remote-endpoint = <0xb3>;
					phandle = <0xb9>;
				};
			};
		};

		panel@0 {
			reg = <0x00>;
			backlight = <0xb4>;
			enable-gpios = <0xb5 0x19 0x00>;
			pinctrl-names = "default";
			pinctrl-0 = <0xb6>;
			compatible = "innolux,p097pfg";
			avdd-supply = <0xb7>;
			avee-supply = <0xb8>;

			ports {
				#address-cells = <0x01>;
				#size-cells = <0x00>;

				port@0 {
					reg = <0x00>;

					endpoint {
						remote-endpoint = <0xb9>;
						phandle = <0xb3>;
					};
				};

				port@1 {
					reg = <0x01>;

					endpoint {
						remote-endpoint = <0xba>;
						phandle = <0xbd>;
					};
				};
			};
		};
	};

	dsi@ff968000 {
		compatible = "rockchip,rk3399-mipi-dsi\0snps,dw-mipi-dsi";
		reg = <0x00 0xff968000 0x00 0x8000>;
		interrupts = <0x00 0x2e 0x04 0x00>;
		clocks = <0x08 0xa2 0x08 0x171 0x08 0xa4 0x08 0x16f>;
		clock-names = "ref\0pclk\0phy_cfg\0grf";
		power-domains = <0x22 0x0f>;
		resets = <0x08 0xfc>;
		reset-names = "apb";
		rockchip,grf = <0x23>;
		#address-cells = <0x01>;
		#size-cells = <0x00>;
		#phy-cells = <0x00>;
		status = "okay";
		phandle = <0xac>;

		ports {
			#address-cells = <0x01>;
			#size-cells = <0x00>;

			port@0 {
				reg = <0x00>;
				#address-cells = <0x01>;
				#size-cells = <0x00>;

				endpoint@0 {
					reg = <0x00>;
					remote-endpoint = <0xbb>;
					phandle = <0xa5>;
				};

				endpoint@1 {
					reg = <0x01>;
					remote-endpoint = <0xbc>;
					phandle = <0x9f>;
				};
			};

			port@1 {
				reg = <0x01>;

				endpoint {
					remote-endpoint = <0xbd>;
					phandle = <0xba>;
				};
			};
		};
	};

	dp@ff970000 {
		compatible = "rockchip,rk3399-edp";
		reg = <0x00 0xff970000 0x00 0x8000>;
		interrupts = <0x00 0x0a 0x04 0x00>;
		clocks = <0x08 0x16a 0x08 0x16c 0x08 0x16f>;
		clock-names = "dp\0pclk\0grf";
		pinctrl-names = "default";
		pinctrl-0 = <0xbe>;
		power-domains = <0x22 0x19>;
		resets = <0x08 0x11d>;
		reset-names = "dp";
		rockchip,grf = <0x23>;
		status = "disabled";

		ports {
			#address-cells = <0x01>;
			#size-cells = <0x00>;

			port@0 {
				reg = <0x00>;
				#address-cells = <0x01>;
				#size-cells = <0x00>;

				endpoint@0 {
					reg = <0x00>;
					remote-endpoint = <0xbf>;
					phandle = <0xa2>;
				};

				endpoint@1 {
					reg = <0x01>;
					remote-endpoint = <0xc0>;
					phandle = <0x9d>;
				};
			};

			port@1 {
				reg = <0x01>;
			};
		};
	};

	gpu@ff9a0000 {
		compatible = "rockchip,rk3399-mali\0arm,mali-t860";
		reg = <0x00 0xff9a0000 0x00 0x10000>;
		interrupts = <0x00 0x14 0x04 0x00 0x00 0x15 0x04 0x00 0x00 0x13 0x04 0x00>;
		interrupt-names = "job\0mmu\0gpu";
		clocks = <0x08 0xd0>;
		#cooling-cells = <0x02>;
		dynamic-power-coefficient = <0xa50>;
		power-domains = <0x22 0x23>;
		status = "okay";
		operating-points-v2 = <0xc1>;
		mali-supply = <0xc2>;
		phandle = <0x6d>;
	};

	pinctrl {
		compatible = "rockchip,rk3399-pinctrl";
		rockchip,grf = <0x23>;
		rockchip,pmu = <0x13>;
		#address-cells = <0x02>;
		#size-cells = <0x02>;
		ranges;
		pinctrl-names = "default";
		pinctrl-0 = <0xc3 0xc4 0xc5>;

		gpio@ff720000 {
			compatible = "rockchip,gpio-bank";
			reg = <0x00 0xff720000 0x00 0x100>;
			clocks = <0x85 0x17>;
			interrupts = <0x00 0x0e 0x04 0x00>;
			gpio-controller;
			#gpio-cells = <0x02>;
			interrupt-controller;
			#interrupt-cells = <0x02>;
			gpio-line-names = "CLK_32K_AP\0EC_IN_RW_OD\0SPK_PA_EN\0WLAN_PERST_1V8_L\0WLAN_PD_1V8_L\0WLAN_RF_KILL_1V8_L\0BIGCPU_DVS_PWM\0SD_CD_L_JTAG_EN\0BT_EN_BT_RF_KILL_1V8_L\0PMUIO2_33_18_L_PP3300_S0_EN\0TOUCH_RESET_L\0AP_EC_WARM_RESET_REQ\0PEN_RESET_L\0AP_FLASH_WP_L";
			phandle = <0x1c>;
		};

		gpio@ff730000 {
			compatible = "rockchip,gpio-bank";
			reg = <0x00 0xff730000 0x00 0x100>;
			clocks = <0x85 0x18>;
			interrupts = <0x00 0x0f 0x04 0x00>;
			gpio-controller;
			#gpio-cells = <0x02>;
			interrupt-controller;
			#interrupt-cells = <0x02>;
			gpio-line-names = "PEN_INT_ODL\0PEN_EJECT_ODL\0BT_HOST_WAKE_1V8_L\0WLAN_HOST_WAKE_1V8_L\0TOUCH_INT_ODL\0AP_EC_S3_S0_L\0AP_EC_OVERTEMP\0AP_SPI_FLASH_MISO\0AP_SPI_FLASH_MOSI_R\0AP_SPI_FLASH_CLK_R\0AP_SPI_FLASH_CS_L_R\0SD_CARD_DET_ODL\0\0AP_EXPANSION_IO1\0AP_EXPANSION_IO2\0AP_I2C_DISP_SDA\0AP_I2C_DISP_SCL\0H1_INT_ODL\0EC_AP_INT_ODL\0LITCPU_DVS_PWM\0AP_I2C_AUDIO_SDA\0AP_I2C_AUDIO_SCL\0AP_EXPANSION_IO3\0HEADSET_INT_ODL\0AP_EXPANSION_IO4";
			phandle = <0x29>;
		};

		gpio@ff780000 {
			compatible = "rockchip,gpio-bank";
			reg = <0x00 0xff780000 0x00 0x100>;
			clocks = <0x08 0x150>;
			interrupts = <0x00 0x10 0x04 0x00>;
			gpio-controller;
			#gpio-cells = <0x02>;
			interrupt-controller;
			#interrupt-cells = <0x02>;
			gpio-line-names = "AP_I2C_PEN_SDA\0AP_I2C_PEN_SCL\0SD_IO_PWR_EN\0UCAM_RST_L\0PP1250_CAM_EN\0WCAM_RST_L\0AP_EXPANSION_IO5\0AP_I2C_CAM_SDA\0AP_I2C_CAM_SCL\0AP_H1_SPI_MISO\0AP_H1_SPI_MOSI\0AP_H1_SPI_CLK\0AP_H1_SPI_CS_L\0\0\0\0UART_EXPANSION_TX_AP_RX\0UART_AP_TX_EXPANSION_RX\0UART_EXPANSION_RTS_AP_CTS\0UART_AP_RTS_EXPANSION_CTS\0AP_SPI_EC_MISO\0AP_SPI_EC_MOSI\0AP_SPI_EC_CLK\0AP_SPI_EC_CS_L\0PP2800_CAM_EN\0CLK_24M_CAM\0WLAN_PCIE_CLKREQ_1V8_L\0\0SD_PWR_3000_1800_L";
			phandle = <0x48>;
		};

		gpio@ff788000 {
			compatible = "rockchip,gpio-bank";
			reg = <0x00 0xff788000 0x00 0x100>;
			clocks = <0x08 0x151>;
			interrupts = <0x00 0x11 0x04 0x00>;
			gpio-controller;
			#gpio-cells = <0x02>;
			interrupt-controller;
			#interrupt-cells = <0x02>;
			gpio-line-names = "\0\0\0\0\0\0\0\0\0\0\0\0\0\0\0\0\0\0\0\0\0\0\0\0I2S0_SCLK\0I2S0_LRCK_RX\0I2S0_LRCK_TX\0I2S0_SDI_0\0STRAP_LCDBIAS_L\0STRAP_FEATURE_1\0STRAP_FEATURE_2\0I2S0_SDO_0";
		};

		gpio@ff790000 {
			compatible = "rockchip,gpio-bank";
			reg = <0x00 0xff790000 0x00 0x100>;
			clocks = <0x08 0x152>;
			interrupts = <0x00 0x12 0x04 0x00>;
			gpio-controller;
			#gpio-cells = <0x02>;
			interrupt-controller;
			#interrupt-cells = <0x02>;
			gpio-line-names = "I2S_MCLK\0AP_I2C_EXPANSION_SDA\0AP_I2C_EXPANSION_SCL\0DMIC_EN\0\0\0\0\0\0\0\0\0\0\0\0\0AP_I2C_TS_SDA\0AP_I2C_TS_SCL\0GPU_DVS_PWM\0UART_DBG_TX_AP_RX\0UART_AP_TX_DBG_RX\0BL_EN\0BL_PWM\0\0\0DISPLAY_RST_L\0\0PPVARP_LCD_EN\0PPVARN_LCD_EN\0SD_SLOT_PWR_EN";
			phandle = <0xb5>;
		};

		pcfg-pull-up {
			bias-pull-up;
			phandle = <0xca>;
		};

		pcfg-pull-down {
			bias-pull-down;
			phandle = <0xcc>;
		};

		pcfg-pull-none {
			bias-disable;
			phandle = <0xc6>;
		};

		pcfg-pull-none-12ma {
			bias-disable;
			drive-strength = <0x0c>;
			phandle = <0xc8>;
		};

		pcfg-pull-none-13ma {
			bias-disable;
			drive-strength = <0x0d>;
			phandle = <0xc7>;
		};

		pcfg-pull-none-18ma {
			bias-disable;
			drive-strength = <0x12>;
		};

		pcfg-pull-none-20ma {
			bias-disable;
			drive-strength = <0x14>;
		};

		pcfg-pull-up-2ma {
			bias-pull-up;
			drive-strength = <0x02>;
		};

		pcfg-pull-up-8ma {
			bias-pull-up;
			drive-strength = <0x08>;
		};

		pcfg-pull-up-18ma {
			bias-pull-up;
			drive-strength = <0x12>;
		};

		pcfg-pull-up-20ma {
			bias-pull-up;
			drive-strength = <0x14>;
		};

		pcfg-pull-down-4ma {
			bias-pull-down;
			drive-strength = <0x04>;
		};

		pcfg-pull-down-8ma {
			bias-pull-down;
			drive-strength = <0x08>;
		};

		pcfg-pull-down-12ma {
			bias-pull-down;
			drive-strength = <0x0c>;
		};

		pcfg-pull-down-18ma {
			bias-pull-down;
			drive-strength = <0x12>;
		};

		pcfg-pull-down-20ma {
			bias-pull-down;
			drive-strength = <0x14>;
		};

		pcfg-output-high {
			output-high;
			phandle = <0xcd>;
		};

		pcfg-output-low {
			output-low;
		};

		pcfg-input-enable {
			input-enable;
		};

		pcfg-input-pull-up {
			input-enable;
			bias-pull-up;
		};

		pcfg-input-pull-down {
			input-enable;
			bias-pull-down;
		};

		clock {

			clk-32k {
				rockchip,pins = <0x00 0x00 0x02 0xc6>;
				phandle = <0xc4>;
			};
		};

		cif {

			cif-clkin {
				rockchip,pins = <0x02 0x0a 0x03 0xc6>;
			};

			cif-clkouta {
				rockchip,pins = <0x02 0x0b 0x03 0xc6>;
			};
		};

		edp {

			edp-hpd {
				rockchip,pins = <0x04 0x17 0x02 0xc6>;
				phandle = <0xbe>;
			};
		};

		gmac {

			rgmii-pins {
				rockchip,pins = <0x03 0x11 0x01 0xc7 0x03 0x0e 0x01 0xc6 0x03 0x0d 0x01 0xc6 0x03 0x0c 0x01 0xc7 0x03 0x0b 0x01 0xc6 0x03 0x09 0x01 0xc6 0x03 0x08 0x01 0xc6 0x03 0x07 0x01 0xc6 0x03 0x06 0x01 0xc6 0x03 0x05 0x01 0xc7 0x03 0x04 0x01 0xc7 0x03 0x03 0x01 0xc6 0x03 0x02 0x01 0xc6 0x03 0x01 0x01 0xc7 0x03 0x00 0x01 0xc7>;
			};

			rmii-pins {
				rockchip,pins = <0x03 0x0d 0x01 0xc6 0x03 0x0c 0x01 0xc7 0x03 0x0b 0x01 0xc6 0x03 0x0a 0x01 0xc6 0x03 0x09 0x01 0xc6 0x03 0x08 0x01 0xc6 0x03 0x07 0x01 0xc6 0x03 0x06 0x01 0xc6 0x03 0x05 0x01 0xc7 0x03 0x04 0x01 0xc7>;
			};
		};

		i2c0 {

			i2c0-xfer {
				rockchip,pins = <0x01 0x0f 0x02 0xc6 0x01 0x10 0x02 0xc6>;
				phandle = <0x8b>;
			};
		};

		i2c1 {

			i2c1-xfer {
				rockchip,pins = <0x04 0x02 0x01 0xc6 0x04 0x01 0x01 0xc6>;
				phandle = <0x3a>;
			};
		};

		i2c2 {

			i2c2-xfer {
				rockchip,pins = <0x02 0x01 0x02 0xc8 0x02 0x00 0x02 0xc8>;
				phandle = <0x3b>;
			};
		};

		i2c3 {

			i2c3-xfer {
				rockchip,pins = <0x04 0x11 0x01 0xc6 0x04 0x10 0x01 0xc6>;
				phandle = <0x3e>;
			};
		};

		i2c4 {

			i2c4-xfer {
				rockchip,pins = <0x01 0x0c 0x01 0xc6 0x01 0x0b 0x01 0xc6>;
				phandle = <0x8c>;
			};
		};

		i2c5 {

			i2c5-xfer {
				rockchip,pins = <0x03 0x0b 0x02 0xc6 0x03 0x0a 0x02 0xc6>;
				phandle = <0x41>;
			};
		};

		i2c6 {

			i2c6-xfer {
				rockchip,pins = <0x02 0x0a 0x02 0xc6 0x02 0x09 0x02 0xc6>;
				phandle = <0x42>;
			};
		};

		i2c7 {

			i2c7-xfer {
				rockchip,pins = <0x02 0x08 0x02 0xc6 0x02 0x07 0x02 0xc6>;
				phandle = <0x43>;
			};
		};

		i2c8 {

			i2c8-xfer {
				rockchip,pins = <0x01 0x15 0x01 0xc6 0x01 0x14 0x01 0xc6>;
				phandle = <0x8d>;
			};
		};

		i2s0 {

			i2s0-2ch-bus {
				rockchip,pins = <0x03 0x18 0x01 0xc6 0x03 0x19 0x01 0xc6 0x03 0x1a 0x01 0xc6 0x03 0x1b 0x01 0xc6 0x03 0x1f 0x01 0xc6 0x04 0x00 0x01 0xc6>;
			};

			i2s0-2ch-bus-bclk-off {
				rockchip,pins = <0x03 0x18 0x00 0xc6 0x03 0x19 0x01 0xc6 0x03 0x1a 0x01 0xc6 0x03 0x1b 0x01 0xc6 0x03 0x1f 0x01 0xc6 0x04 0x00 0x01 0xc6>;
			};

			i2s0-8ch-bus {
				rockchip,pins = <0x03 0x18 0x01 0xc9 0x03 0x19 0x01 0xc9 0x03 0x1a 0x01 0xc9 0x03 0x1b 0x01 0xc9 0x03 0x1f 0x01 0xc9 0x04 0x00 0x01 0xc9>;
				phandle = <0x98>;
			};

			i2s0-8ch-bus-bclk-off {
				rockchip,pins = <0x03 0x18 0x00 0xc9 0x03 0x19 0x01 0xc9 0x03 0x1a 0x01 0xc9 0x03 0x1b 0x01 0xc9 0x03 0x1f 0x01 0xc9 0x04 0x00 0x01 0xc9>;
				phandle = <0x99>;
			};
		};

		i2s1 {

			i2s1-2ch-bus {
				rockchip,pins = <0x04 0x03 0x01 0xc6 0x04 0x04 0x01 0xc6 0x04 0x05 0x01 0xc6 0x04 0x06 0x01 0xc6 0x04 0x07 0x01 0xc6>;
				phandle = <0x9a>;
			};

			i2s1-2ch-bus-bclk-off {
				rockchip,pins = <0x04 0x03 0x00 0xc6 0x04 0x04 0x01 0xc6 0x04 0x05 0x01 0xc6 0x04 0x06 0x01 0xc6 0x04 0x07 0x01 0xc6>;
			};
		};

		sdio0 {

			sdio0-bus1 {
				rockchip,pins = <0x02 0x14 0x01 0xca>;
			};

			sdio0-bus4 {
				rockchip,pins = <0x02 0x14 0x01 0xca 0x02 0x15 0x01 0xca 0x02 0x16 0x01 0xca 0x02 0x17 0x01 0xca>;
			};

			sdio0-cmd {
				rockchip,pins = <0x02 0x18 0x01 0xca>;
			};

			sdio0-clk {
				rockchip,pins = <0x02 0x19 0x01 0xc6>;
			};

			sdio0-cd {
				rockchip,pins = <0x02 0x1a 0x01 0xca>;
			};

			sdio0-pwr {
				rockchip,pins = <0x02 0x1b 0x01 0xca>;
			};

			sdio0-bkpwr {
				rockchip,pins = <0x02 0x1c 0x01 0xca>;
			};

			sdio0-wp {
				rockchip,pins = <0x00 0x03 0x01 0xca>;
			};

			sdio0-int {
				rockchip,pins = <0x00 0x04 0x01 0xca>;
			};
		};

		sdmmc {

			sdmmc-bus1 {
				rockchip,pins = <0x04 0x08 0x01 0xca>;
			};

			sdmmc-bus4 {
				rockchip,pins = <0x04 0x08 0x01 0xcb 0x04 0x09 0x01 0xcb 0x04 0x0a 0x01 0xcb 0x04 0x0b 0x01 0xcb>;
				phandle = <0x28>;
			};

			sdmmc-clk {
				rockchip,pins = <0x04 0x0c 0x01 0xcb>;
				phandle = <0x24>;
			};

			sdmmc-cmd {
				rockchip,pins = <0x04 0x0d 0x01 0xcb>;
				phandle = <0x25>;
			};

			sdmmc-cd {
				rockchip,pins = <0x00 0x07 0x01 0xc6>;
				phandle = <0x26>;
			};

			sdmmc-wp {
				rockchip,pins = <0x00 0x08 0x01 0xca>;
			};

			sdmmc-cd-pin {
				rockchip,pins = <0x01 0x0b 0x00 0xca>;
				phandle = <0x27>;
			};
		};

		suspend {

			ap-pwroff {
				rockchip,pins = <0x01 0x05 0x01 0xc6>;
				phandle = <0xc3>;
			};

			ddrio-pwroff {
				rockchip,pins = <0x00 0x01 0x01 0xc6>;
			};
		};

		spdif {

			spdif-bus {
				rockchip,pins = <0x04 0x15 0x01 0xc6>;
			};

			spdif-bus-1 {
				rockchip,pins = <0x03 0x10 0x03 0xc6>;
			};
		};

		spi0 {

			spi0-clk {
				rockchip,pins = <0x03 0x06 0x02 0xca>;
				phandle = <0x51>;
			};

			spi0-cs0 {
				rockchip,pins = <0x03 0x07 0x02 0xca>;
				phandle = <0x54>;
			};

			spi0-cs1 {
				rockchip,pins = <0x03 0x08 0x02 0xca>;
			};

			spi0-tx {
				rockchip,pins = <0x03 0x05 0x02 0xca>;
				phandle = <0x52>;
			};

			spi0-rx {
				rockchip,pins = <0x03 0x04 0x02 0xca>;
				phandle = <0x53>;
			};
		};

		spi1 {

			spi1-clk {
				rockchip,pins = <0x01 0x09 0x02 0xca>;
				phandle = <0x55>;
			};

			spi1-cs0 {
				rockchip,pins = <0x01 0x0a 0x02 0xca>;
				phandle = <0x58>;
			};

			spi1-rx {
				rockchip,pins = <0x01 0x07 0x02 0xca>;
				phandle = <0x57>;
			};

			spi1-tx {
				rockchip,pins = <0x01 0x08 0x02 0xca>;
				phandle = <0x56>;
			};

			spi1-sleep {
				rockchip,pins = <0x01 0x09 0x00 0xcc 0x01 0x0a 0x00 0xcc 0x01 0x07 0x00 0xcc 0x01 0x08 0x00 0xcc>;
				phandle = <0x59>;
			};
		};

		spi2 {

			spi2-clk {
				rockchip,pins = <0x02 0x0b 0x01 0xca>;
				phandle = <0x5a>;
			};

			spi2-cs0 {
				rockchip,pins = <0x02 0x0c 0x01 0xca>;
				phandle = <0x5d>;
			};

			spi2-rx {
				rockchip,pins = <0x02 0x09 0x01 0xca>;
				phandle = <0x5c>;
			};

			spi2-tx {
				rockchip,pins = <0x02 0x0a 0x01 0xca>;
				phandle = <0x5b>;
			};
		};

		spi3 {

			spi3-clk {
				rockchip,pins = <0x01 0x11 0x01 0xca>;
				phandle = <0x86>;
			};

			spi3-cs0 {
				rockchip,pins = <0x01 0x12 0x01 0xca>;
				phandle = <0x89>;
			};

			spi3-rx {
				rockchip,pins = <0x01 0x0f 0x01 0xca>;
				phandle = <0x88>;
			};

			spi3-tx {
				rockchip,pins = <0x01 0x10 0x01 0xca>;
				phandle = <0x87>;
			};
		};

		spi4 {

			spi4-clk {
				rockchip,pins = <0x03 0x02 0x02 0xca>;
				phandle = <0x5f>;
			};

			spi4-cs0 {
				rockchip,pins = <0x03 0x03 0x02 0xca>;
				phandle = <0x62>;
			};

			spi4-rx {
				rockchip,pins = <0x03 0x00 0x02 0xca>;
				phandle = <0x61>;
			};

			spi4-tx {
				rockchip,pins = <0x03 0x01 0x02 0xca>;
				phandle = <0x60>;
			};
		};

		spi5 {

			spi5-clk {
				rockchip,pins = <0x02 0x16 0x02 0xca>;
				phandle = <0x64>;
			};

			spi5-cs0 {
				rockchip,pins = <0x02 0x17 0x02 0xca>;
				phandle = <0x67>;
			};

			spi5-rx {
				rockchip,pins = <0x02 0x14 0x02 0xca>;
				phandle = <0x66>;
			};

			spi5-tx {
				rockchip,pins = <0x02 0x15 0x02 0xca>;
				phandle = <0x65>;
			};
		};

		testclk {

			test-clkout0 {
				rockchip,pins = <0x00 0x00 0x01 0xc6>;
			};

			test-clkout1 {
				rockchip,pins = <0x02 0x19 0x02 0xc6>;
				phandle = <0x44>;
			};

			test-clkout2 {
				rockchip,pins = <0x00 0x08 0x03 0xc6>;
			};
		};

		tsadc {

			otp-pin {
				rockchip,pins = <0x01 0x06 0x00 0xc6>;
				phandle = <0x6e>;
			};

			otp-out {
				rockchip,pins = <0x01 0x06 0x01 0xc6>;
				phandle = <0x6f>;
			};
		};

		uart0 {

			uart0-xfer {
				rockchip,pins = <0x02 0x10 0x01 0xca 0x02 0x11 0x01 0xc6>;
				phandle = <0x4c>;
			};

			uart0-cts {
				rockchip,pins = <0x02 0x12 0x01 0xc6>;
			};

			uart0-rts {
				rockchip,pins = <0x02 0x13 0x01 0xc6>;
			};
		};

		uart1 {

			uart1-xfer {
				rockchip,pins = <0x03 0x0c 0x02 0xca 0x03 0x0d 0x02 0xc6>;
				phandle = <0x4d>;
			};
		};

		uart2a {

			uart2a-xfer {
				rockchip,pins = <0x04 0x08 0x02 0xca 0x04 0x09 0x02 0xc6>;
			};
		};

		uart2b {

			uart2b-xfer {
				rockchip,pins = <0x04 0x10 0x02 0xca 0x04 0x11 0x02 0xc6>;
			};
		};

		uart2c {

			uart2c-xfer {
				rockchip,pins = <0x04 0x13 0x01 0xca 0x04 0x14 0x01 0xc6>;
				phandle = <0x4e>;
			};
		};

		uart3 {

			uart3-xfer {
				rockchip,pins = <0x03 0x0e 0x02 0xca 0x03 0x0f 0x02 0xc6>;
				phandle = <0x4f>;
			};

			uart3-cts {
				rockchip,pins = <0x03 0x10 0x02 0xc6>;
			};

			uart3-rts {
				rockchip,pins = <0x03 0x11 0x02 0xc6>;
			};
		};

		uart4 {

			uart4-xfer {
				rockchip,pins = <0x01 0x07 0x01 0xca 0x01 0x08 0x01 0xc6>;
				phandle = <0x8a>;
			};
		};

		uarthdcp {

			uarthdcp-xfer {
				rockchip,pins = <0x04 0x15 0x02 0xca 0x04 0x16 0x02 0xc6>;
			};
		};

		pwm0 {

			pwm0-pin {
				rockchip,pins = <0x04 0x12 0x01 0xc6>;
				phandle = <0x90>;
			};

			pwm0-pin-pull-down {
				rockchip,pins = <0x04 0x12 0x01 0xcc>;
			};

			vop0-pwm-pin {
				rockchip,pins = <0x04 0x12 0x02 0xc6>;
			};

			vop1-pwm-pin {
				rockchip,pins = <0x04 0x12 0x03 0xc6>;
			};
		};

		pwm1 {

			pwm1-pin {
				rockchip,pins = <0x04 0x16 0x01 0xc6>;
				phandle = <0x91>;
			};

			pwm1-pin-pull-down {
				rockchip,pins = <0x04 0x16 0x01 0xcc>;
			};
		};

		pwm2 {

			pwm2-pin {
				rockchip,pins = <0x01 0x13 0x01 0xc6>;
				phandle = <0x92>;
			};

			pwm2-pin-pull-down {
				rockchip,pins = <0x01 0x13 0x01 0xcc>;
			};
		};

		pwm3a {

			pwm3a-pin {
				rockchip,pins = <0x00 0x06 0x01 0xc6>;
				phandle = <0x93>;
			};
		};

		pwm3b {

			pwm3b-pin {
				rockchip,pins = <0x01 0x0e 0x01 0xc6>;
			};
		};

		hdmi {

			hdmi-i2c-xfer {
				rockchip,pins = <0x04 0x11 0x03 0xc6 0x04 0x10 0x03 0xc6>;
			};

			hdmi-cec {
				rockchip,pins = <0x04 0x17 0x01 0xc6>;
			};
		};

		pcie {

			pci-clkreqn-cpm {
				rockchip,pins = <0x02 0x1a 0x00 0xc6>;
				phandle = <0x1d>;
			};

			pci-clkreqnb-cpm {
				rockchip,pins = <0x04 0x18 0x00 0xc6>;
				phandle = <0x21>;
			};
		};

		pcfg-pull-none-8ma {
			bias-disable;
			drive-strength = <0x08>;
			phandle = <0xcb>;
		};

		backlight-enable {

			bl-en {
				rockchip,pins = <0x04 0x15 0x00 0xc6>;
				phandle = <0xe7>;
			};
		};

		cros-ec {

			ec-ap-int-l {
				rockchip,pins = <0x01 0x12 0x00 0xca>;
				phandle = <0x68>;
			};
		};

		discrete-regulators {

			sd-io-pwr-en {
				rockchip,pins = <0x02 0x02 0x00 0xc6>;
				phandle = <0xd6>;
			};

			sd-pwr-1800-sel {
				rockchip,pins = <0x02 0x1c 0x00 0xca>;
				phandle = <0xd7>;
			};

			sd-slot-pwr-en {
				rockchip,pins = <0x04 0x1d 0x00 0xc6>;
				phandle = <0xd5>;
			};

			display-rst-l {
				rockchip,pins = <0x04 0x19 0x00 0xcc>;
				phandle = <0xb6>;
			};

			ppvarp-lcd-en {
				rockchip,pins = <0x04 0x1b 0x00 0xc6>;
				phandle = <0xe2>;
			};

			ppvarn-lcd-en {
				rockchip,pins = <0x04 0x1c 0x00 0xc6>;
				phandle = <0xe1>;
			};
		};

		codec {

			headset-int-l {
				rockchip,pins = <0x01 0x17 0x00 0xca>;
				phandle = <0x8e>;
			};

			mic-int {
				rockchip,pins = <0x01 0x0d 0x00 0xcc>;
			};
		};

		max98357a {

			sdmode-en {
				rockchip,pins = <0x00 0x02 0x00 0xcc>;
				phandle = <0xd8>;
			};
		};

		touchscreen {

			touch-int-l {
				rockchip,pins = <0x01 0x04 0x00 0xcc>;
				phandle = <0x3f>;
			};

			touch-reset-l {
				rockchip,pins = <0x00 0x0a 0x00 0xcc>;
				phandle = <0x40>;
			};
		};

		trackpad {

			ap-i2c-tp-pu-en {
				rockchip,pins = <0x03 0x0c 0x00 0xcd>;
			};

			trackpad-int-l {
				rockchip,pins = <0x01 0x04 0x00 0xca>;
			};
		};

		wifi {

			wlan-module-reset-l {
				rockchip,pins = <0x01 0x0b 0x00 0xc6>;
			};

			bt-host-wake-l {
				rockchip,pins = <0x01 0x02 0x00 0xc6>;
				phandle = <0x2f>;
			};

			bt-en-1v8-l {
				rockchip,pins = <0x00 0x08 0x00 0xc6>;
				phandle = <0xe4>;
			};

			wlan-pd-1v8-l {
				rockchip,pins = <0x00 0x04 0x00 0xc6>;
				phandle = <0xe5>;
			};

			wlan-rf-kill-1v8-l {
				rockchip,pins = <0x00 0x05 0x00 0xca>;
				phandle = <0xc5>;
			};

			wifi-perst-l {
				rockchip,pins = <0x00 0x03 0x00 0xc6>;
				phandle = <0x1e>;
			};

			wlan-host-wake-l {
				rockchip,pins = <0x01 0x03 0x00 0xca>;
			};
		};

		write-protect {

			ap-fw-wp {
				rockchip,pins = <0x00 0x0d 0x00 0xc6>;
			};
		};

		pcfg-pull-none-6ma {
			bias-disable;
			drive-strength = <0x06>;
			phandle = <0xc9>;
		};

		camera {

			pp1250-dvdd {
				rockchip,pins = <0x02 0x04 0x00 0xc6>;
				phandle = <0xdf>;
			};

			pp2800-avdd {
				rockchip,pins = <0x02 0x18 0x00 0xc6>;
				phandle = <0xe3>;
			};

			ucam_rst {
				rockchip,pins = <0x02 0x03 0x00 0xc6>;
				phandle = <0x4a>;
			};

			wcam_rst {
				rockchip,pins = <0x02 0x05 0x00 0xc6>;
				phandle = <0x45>;
			};
		};

		digitizer {

			pen-int-odl {
				rockchip,pins = <0x01 0x00 0x00 0xca>;
				phandle = <0x3c>;
			};

			pen-reset-l {
				rockchip,pins = <0x00 0x0c 0x00 0xc6>;
				phandle = <0x3d>;
			};
		};

		dmic {

			dmic-en {
				rockchip,pins = <0x04 0x03 0x00 0xc6>;
				phandle = <0xe9>;
			};
		};

		pen {

			pen-eject-odl {
				rockchip,pins = <0x01 0x01 0x00 0xca>;
				phandle = <0xea>;
			};
		};

		tpm {

			h1-int-od-l {
				rockchip,pins = <0x01 0x11 0x00 0xca>;
				phandle = <0x5e>;
			};
		};
	};

	opp-table-0 {
		compatible = "operating-points-v2";
		opp-shared;
		phandle = <0x0c>;

		opp00 {
			opp-hz = <0x00 0x18519600>;
			opp-microvolt = "\0\f5";
			clock-latency-ns = <0x9c40>;
		};

		opp01 {
			opp-hz = <0x00 0x23c34600>;
			opp-microvolt = <0xc96a8>;
		};

		opp02 {
			opp-hz = <0x00 0x30a32c00>;
			opp-microvolt = <0xcf850>;
		};

		opp03 {
			opp-hz = <0x00 0x3c14dc00>;
			opp-microvolt = <0xdbba0>;
		};

		opp04 {
			opp-hz = <0x00 0x47868c00>;
			opp-microvolt = <0xee098>;
		};

		opp05 {
			opp-hz = <0x00 0x54667200>;
			opp-microvolt = <0x10c8e0>;
			opp-suspend;
		};

		opp06 {
			opp-hz = <0x00 0x5a1f4a00>;
			opp-microvolt = <0x118c30>;
		};
	};

	opp-table-1 {
		compatible = "operating-points-v2";
		opp-shared;
		phandle = <0x0f>;

		opp00 {
			opp-hz = <0x00 0x18519600>;
			opp-microvolt = "\0\f5";
			clock-latency-ns = <0x9c40>;
		};

		opp01 {
			opp-hz = <0x00 0x23c34600>;
			opp-microvolt = "\0\f5";
		};

		opp02 {
			opp-hz = <0x00 0x30a32c00>;
			opp-microvolt = <0xc96a8>;
		};

		opp03 {
			opp-hz = <0x00 0x3c14dc00>;
			opp-microvolt = <0xcf850>;
		};

		opp04 {
			opp-hz = <0x00 0x47868c00>;
			opp-microvolt = <0xdbba0>;
		};

		opp05 {
			opp-hz = <0x00 0x54667200>;
			opp-microvolt = <0xee098>;
		};

		opp06 {
			opp-hz = <0x00 0x5fd82200>;
			opp-microvolt = <0x100590>;
			opp-suspend;
		};

		opp07 {
			opp-hz = <0x00 0x6b49d200>;
			opp-microvolt = <0x118c30>;
		};

		opp08 {
			opp-hz = <0x00 0x7829b800>;
			opp-microvolt = <0x1312d0>;
		};
	};

	opp-table-2 {
		compatible = "operating-points-v2";
		phandle = <0xc1>;

		opp00 {
			opp-hz = <0x00 0xbebc200>;
			opp-microvolt = "\0\f5";
		};

		opp01 {
			opp-hz = <0x00 0x11b3dc40>;
			opp-microvolt = "\0\f5";
		};

		opp02 {
			opp-hz = <0x00 0x17d78400>;
			opp-microvolt = <0xc96a8>;
		};

		opp03 {
			opp-hz = <0x00 0x1dcd6500>;
			opp-microvolt = <0xcf850>;
		};

		opp04 {
			opp-hz = <0x00 0x23c34600>;
			opp-microvolt = <0xe1d48>;
		};

		opp05 {
			opp-hz = <0x00 0x2faf0800>;
			opp-microvolt = <0x106738>;
		};
	};

	opp-table-3 {
		compatible = "operating-points-v2";
		phandle = <0x15>;

		opp00 {
			opp-hz = <0x00 0x17d78400>;
			opp-microvolt = <0xdbba0>;
		};

		opp01 {
			opp-hz = <0x00 0x27b25a80>;
			opp-microvolt = <0xdbba0>;
		};

		opp02 {
			opp-hz = <0x00 0x2faf0800>;
			opp-microvolt = <0xdbba0>;
		};

		opp03 {
			opp-hz = <0x00 0x37502800>;
			opp-microvolt = <0xdbba0>;
			opp-suspend;
		};
	};

	chosen {
		stdout-path = "serial2:115200n8";
	};

	ppvar-sys {
		compatible = "regulator-fixed";
		regulator-name = "ppvar_sys";
		regulator-always-on;
		regulator-boot-on;
		phandle = <0xce>;
	};

	pp1200-lpddr {
		compatible = "regulator-fixed";
		regulator-name = "pp1200_lpddr";
		regulator-always-on;
		regulator-boot-on;
		regulator-min-microvolt = <0x124f80>;
		regulator-max-microvolt = <0x124f80>;
		vin-supply = <0xce>;
	};

	pp1800 {
		compatible = "regulator-fixed";
		regulator-name = "pp1800";
		regulator-always-on;
		regulator-boot-on;
		regulator-min-microvolt = <0x1b7740>;
		regulator-max-microvolt = <0x1b7740>;
		vin-supply = <0xce>;
		phandle = <0x20>;
	};

	pp3300 {
		compatible = "regulator-fixed";
		regulator-name = "pp3300";
		regulator-always-on;
		regulator-boot-on;
		regulator-min-microvolt = <0x325aa0>;
		regulator-max-microvolt = <0x325aa0>;
		vin-supply = <0xce>;
		phandle = <0x8f>;
	};

	pp5000 {
		compatible = "regulator-fixed";
		regulator-name = "pp5000";
		regulator-always-on;
		regulator-boot-on;
		regulator-min-microvolt = <0x4c4b40>;
		regulator-max-microvolt = <0x4c4b40>;
		vin-supply = <0xce>;
	};

	ppvar-bigcpu-pwm {
		compatible = "pwm-regulator";
		regulator-name = "ppvar_bigcpu_pwm";
		pwms = <0xcf 0x00 0xd09 0x00>;
		pwm-supply = <0xce>;
		pwm-dutycycle-range = <0x64 0x00>;
		pwm-dutycycle-unit = <0x64>;
		regulator-always-on;
		regulator-boot-on;
		regulator-min-microvolt = <0xc354a>;
		regulator-max-microvolt = <0x13d31a>;
		phandle = <0xd0>;
	};

	ppvar-bigcpu {
		compatible = "vctrl-regulator";
		regulator-name = "ppvar_bigcpu";
		regulator-min-microvolt = <0xc354a>;
		regulator-max-microvolt = <0x13d31a>;
		ctrl-supply = <0xd0>;
		ctrl-voltage-range = <0xc354a 0x13d31a>;
		regulator-settling-time-up-us = <0x142>;
		phandle = <0x10>;
	};

	ppvar-litcpu-pwm {
		compatible = "pwm-regulator";
		regulator-name = "ppvar_litcpu_pwm";
		pwms = <0xd1 0x00 0xd09 0x00>;
		pwm-supply = <0xce>;
		pwm-dutycycle-range = <0x64 0x00>;
		pwm-dutycycle-unit = <0x64>;
		regulator-always-on;
		regulator-boot-on;
		regulator-min-microvolt = <0xc3d4a>;
		regulator-max-microvolt = <0x124e04>;
		phandle = <0xd2>;
	};

	ppvar-litcpu {
		compatible = "vctrl-regulator";
		regulator-name = "ppvar_litcpu";
		regulator-min-microvolt = <0xc3d4a>;
		regulator-max-microvolt = <0x124e04>;
		ctrl-supply = <0xd2>;
		ctrl-voltage-range = <0xc3d4a 0x124e04>;
		regulator-settling-time-up-us = <0x180>;
		phandle = <0x0d>;
	};

	ppvar-gpu-pwm {
		compatible = "pwm-regulator";
		regulator-name = "ppvar_gpu_pwm";
		pwms = <0xd3 0x00 0xd09 0x00>;
		pwm-supply = <0xce>;
		pwm-dutycycle-range = <0x64 0x00>;
		pwm-dutycycle-unit = <0x64>;
		regulator-always-on;
		regulator-boot-on;
		regulator-min-microvolt = <0xc3370>;
		regulator-max-microvolt = <0x10c750>;
		phandle = <0xd4>;
	};

	ppvar-gpu {
		compatible = "vctrl-regulator";
		regulator-name = "ppvar_gpu";
		regulator-min-microvolt = <0xc3370>;
		regulator-max-microvolt = <0x10c750>;
		ctrl-supply = <0xd4>;
		ctrl-voltage-range = <0xc3370 0x10c750>;
		regulator-settling-time-up-us = <0x186>;
		phandle = <0xc2>;
	};

	pp900-ap {
	};

	pp3000-sd-slot {
		compatible = "regulator-fixed";
		regulator-name = "pp3000_sd_slot";
		pinctrl-names = "default";
		pinctrl-0 = <0xd5>;
		enable-active-high;
		gpio = <0xb5 0x1d 0x00>;
		vin-supply = <0x8f>;
		phandle = <0x2a>;
	};

	ppvar-sd-card-io {
		compatible = "regulator-gpio";
		regulator-name = "ppvar_sd_card_io";
		pinctrl-names = "default";
		pinctrl-0 = <0xd6 0xd7>;
		enable-active-high;
		enable-gpios = <0x48 0x02 0x00>;
		gpios = <0x48 0x1c 0x00>;
		states = <0x1b7740 0x00 0x325aa0 0x01>;
		regulator-min-microvolt = <0x1b7740>;
		regulator-max-microvolt = <0x325aa0>;
		phandle = <0x2b>;
	};

	pp3300-trackpad {
	};

	ap-rtc-clk {
		compatible = "fixed-clock";
		clock-frequency = <0x8000>;
		clock-output-names = "xin32k";
		#clock-cells = <0x00>;
	};

	max98357a {
		compatible = "maxim,max98357a";
		pinctrl-names = "default";
		pinctrl-0 = <0xd8>;
		sdmode-gpios = <0x1c 0x02 0x00>;
		sdmode-delay = <0x02>;
		#sound-dai-cells = <0x00>;
		status = "okay";
		phandle = <0xdb>;
	};

	sound {
		compatible = "rockchip,rk3399-gru-sound";
		rockchip,cpu = <0xd9 0xda>;
		rockchip,codec = <0xdb 0xdc 0xdd 0xde>;
	};

	pp1250-s3 {
		compatible = "regulator-fixed";
		regulator-name = "pp1250_s3";
		regulator-always-on;
		regulator-boot-on;
		regulator-min-microvolt = <0x1312d0>;
		regulator-max-microvolt = <0x1312d0>;
		vin-supply = <0xce>;
		phandle = <0xe0>;
	};

	pp1250-dvdd {
		compatible = "regulator-fixed";
		regulator-name = "pp1250_dvdd";
		pinctrl-names = "default";
		pinctrl-0 = <0xdf>;
		enable-active-high;
		gpio = <0x48 0x04 0x00>;
		startup-delay-us = <0x3e8>;
		vin-supply = <0xe0>;
		phandle = <0x47>;
	};

	pp900-s0 {
		compatible = "regulator-fixed";
		regulator-name = "pp900_s0";
		regulator-always-on;
		regulator-boot-on;
		regulator-min-microvolt = <0xdbba0>;
		regulator-max-microvolt = <0xdbba0>;
		vin-supply = <0xce>;
		phandle = <0x16>;
	};

	ppvarn-lcd {
		compatible = "regulator-fixed";
		regulator-name = "ppvarn_lcd";
		pinctrl-names = "default";
		pinctrl-0 = <0xe1>;
		enable-active-high;
		gpio = <0xb5 0x1c 0x00>;
		vin-supply = <0xce>;
		phandle = <0xb8>;
	};

	ppvarp-lcd {
		compatible = "regulator-fixed";
		regulator-name = "ppvarp_lcd";
		pinctrl-names = "default";
		pinctrl-0 = <0xe2>;
		enable-active-high;
		gpio = <0xb5 0x1b 0x00>;
		vin-supply = <0xce>;
		phandle = <0xb7>;
	};

	pp900-s3 {
		compatible = "regulator-fixed";
		regulator-name = "pp900_s3";
		regulator-always-on;
		regulator-boot-on;
		regulator-min-microvolt = <0xdbba0>;
		regulator-max-microvolt = <0xdbba0>;
		vin-supply = <0x20>;
	};

	pp2800-avdd {
		compatible = "regulator-fixed";
		regulator-name = "pp2800_avdd";
		pinctrl-names = "default";
		pinctrl-0 = <0xe3>;
		enable-active-high;
		gpio = <0x48 0x18 0x00>;
		startup-delay-us = <0x64>;
		vin-supply = <0x8f>;
		phandle = <0x46>;
	};

	bt-3v3 {
		compatible = "regulator-fixed";
		regulator-name = "bt_3v3";
		pinctrl-names = "default";
		pinctrl-0 = <0xe4>;
		enable-active-high;
		gpio = <0x1c 0x08 0x00>;
		vin-supply = <0x8f>;
		phandle = <0xe6>;
	};

	wlan-3v3 {
		compatible = "regulator-fixed";
		regulator-name = "wlan_3v3";
		pinctrl-names = "default";
		pinctrl-0 = <0xe5>;
		enable-active-high;
		gpio = <0x1c 0x04 0x00>;
		regulator-enable-ramp-delay = <0x2710>;
		vin-supply = <0xe6>;
		phandle = <0x1f>;
	};

	backlight {
		compatible = "pwm-backlight";
		enable-gpios = <0xb5 0x15 0x00>;
		pinctrl-names = "default";
		pinctrl-0 = <0xe7>;
		pwms = <0xe8 0x00 0xf4240 0x00>;
		phandle = <0xb4>;
	};

	dmic {
		compatible = "dmic-codec";
		dmicen-gpios = <0xb5 0x03 0x00>;
		pinctrl-names = "default";
		pinctrl-0 = <0xe9>;
		wakeup-delay-ms = <0xfa>;
		phandle = <0xdc>;
	};

	gpio-keys {
		compatible = "gpio-keys";
		pinctrl-names = "default";
		pinctrl-0 = <0xea>;

		switch-pen-insert {
			label = "Pen Insert";
			gpios = <0x29 0x01 0x01>;
			linux,code = <0x0f>;
			linux,input-type = <0x05>;
			wakeup-source;
		};
	};
};
